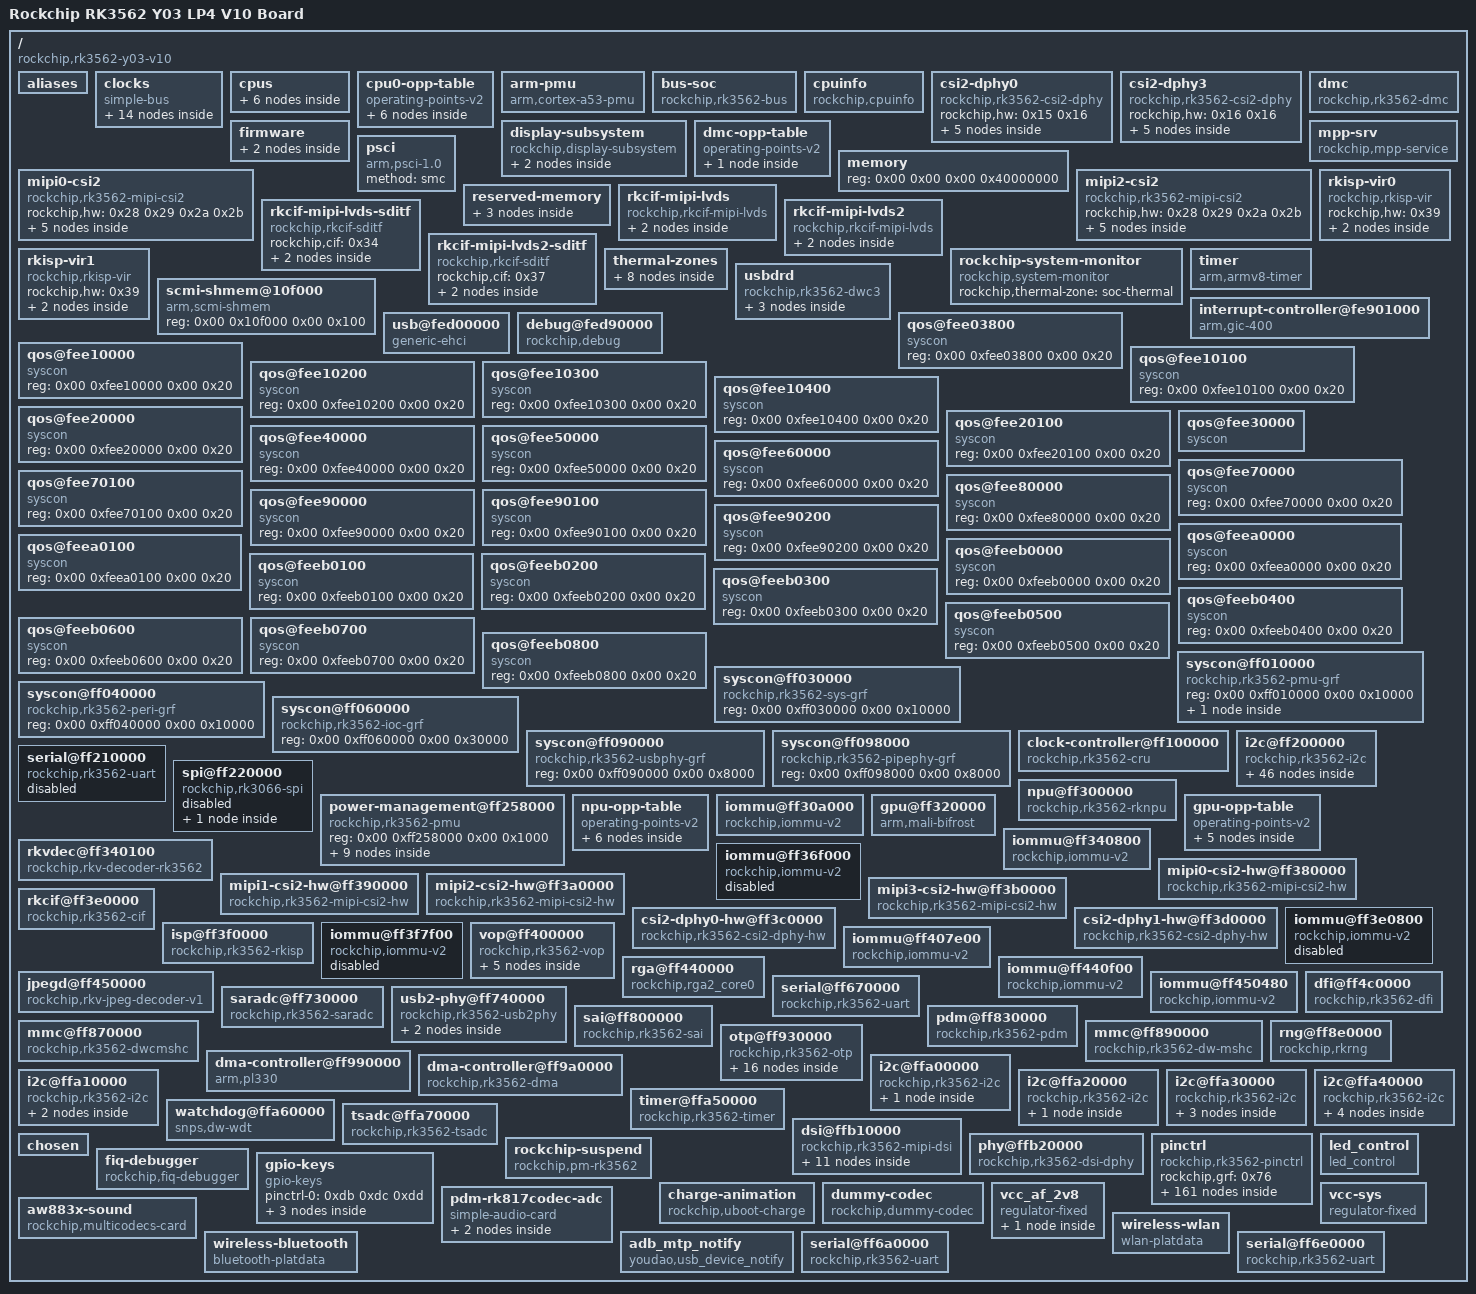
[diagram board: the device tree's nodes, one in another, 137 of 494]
/dts-v1/;

/ {
	compatible = "rockchip,rk3562-y03-v10", "rockchip,rk3562";
	interrupt-parent = <0x01>;
	#address-cells = <0x02>;
	#size-cells = <0x02>;
	model = "Rockchip RK3562 Y03 LP4 V10 Board";

	aliases {
		csi2dphy0 = "/csi2-dphy0";
		csi2dphy3 = "/csi2-dphy3";
		gpio0 = "/pinctrl/gpio@ff260000";
		gpio1 = "/pinctrl/gpio@ff620000";
		gpio2 = "/pinctrl/gpio@ff630000";
		gpio3 = "/pinctrl/gpio@ffac0000";
		gpio4 = "/pinctrl/gpio@ffad0000";
		i2c0 = "/i2c@ff200000";
		i2c1 = "/i2c@ffa00000";
		i2c2 = "/i2c@ffa10000";
		i2c3 = "/i2c@ffa20000";
		i2c4 = "/i2c@ffa30000";
		i2c5 = "/i2c@ffa40000";
		rkcif_mipi_lvds0 = "/rkcif-mipi-lvds";
		rkcif_mipi_lvds2 = "/rkcif-mipi-lvds2";
		serial0 = "/serial@ff210000";
		serial1 = "/serial@ff670000";
		spi0 = "/spi@ff220000";
		mmc0 = "/mmc@ff870000";
		mmc1 = "/mmc@ff890000";
		serial4 = "/serial@ff6a0000";
		serial8 = "/serial@ff6e0000";
	};

	clocks {
		compatible = "simple-bus";
		#address-cells = <0x02>;
		#size-cells = <0x02>;
		ranges;

		xin32k {
			compatible = "fixed-clock";
			#clock-cells = <0x00>;
			clock-frequency = <0x8000>;
			clock-output-names = "xin32k";
		};

		xin24m {
			compatible = "fixed-clock";
			#clock-cells = <0x00>;
			clock-frequency = <0x16e3600>;
			clock-output-names = "xin24m";
		};

		hclk_vepu@ff100324 {
			compatible = "rockchip,rk3562-clock-gate-link";
			reg = <0x00 0xff100324 0x00 0x10>;
			clock-names = "link";
			clocks = <0x02 0x152>;
			#power-domain-cells = <0x01>;
			#clock-cells = <0x00>;
		};

		aclk_vdpu@ff100328 {
			compatible = "rockchip,rk3562-clock-gate-link";
			reg = <0x00 0xff100328 0x00 0x10>;
			clock-names = "link";
			clocks = <0x02 0x12>;
			#power-domain-cells = <0x01>;
			#clock-cells = <0x00>;
		};

		aclk_vi_isp@ff10032c {
			compatible = "rockchip,rk3562-clock-gate-link";
			reg = <0x00 0xff10032c 0x00 0x10>;
			clock-names = "link";
			clocks = <0x02 0x12>;
			#power-domain-cells = <0x01>;
			#clock-cells = <0x00>;
			phandle = <0x03>;
		};

		aclk_vo@ff100334 {
			compatible = "rockchip,rk3562-clock-gate-link";
			reg = <0x00 0xff100334 0x00 0x10>;
			clock-names = "link";
			clocks = <0x02 0x12>;
			#power-domain-cells = <0x01>;
			#clock-cells = <0x00>;
			phandle = <0x04>;
		};

		aclk_vepu@ff100324 {
			compatible = "rockchip,rk3562-clock-gate-link";
			reg = <0x00 0xff100324 0x00 0x10>;
			clock-names = "link";
			clocks = <0x03>;
			#power-domain-cells = <0x01>;
			#clock-cells = <0x00>;
		};

		aclk_rga_jdec@ff100338 {
			compatible = "rockchip,rk3562-clock-gate-link";
			reg = <0x00 0xff100338 0x00 0x10>;
			clock-names = "link";
			clocks = <0x04>;
			#power-domain-cells = <0x01>;
			#clock-cells = <0x00>;
		};

		mclkin-sai0 {
			compatible = "fixed-clock";
			#clock-cells = <0x00>;
			clock-frequency = <0x00>;
			clock-output-names = "mclk_sai0_from_io";
		};

		mclkin-sai1 {
			compatible = "fixed-clock";
			#clock-cells = <0x00>;
			clock-frequency = <0x00>;
			clock-output-names = "mclk_sai1_from_io";
		};

		mclkin-sai2 {
			compatible = "fixed-clock";
			#clock-cells = <0x00>;
			clock-frequency = <0x00>;
			clock-output-names = "mclk_sai2_from_io";
		};

		mclkout-sai0@ff040070 {
			compatible = "rockchip,clk-out";
			reg = <0x00 0xff040070 0x00 0x04>;
			clocks = <0x02 0x79>;
			#clock-cells = <0x00>;
			clock-output-names = "mclk_sai0_to_io";
			rockchip,bit-shift = <0x04>;
			phandle = <0x51>;
		};

		mclkout-sai1@ff040070 {
			compatible = "rockchip,clk-out";
			reg = <0x00 0xff040070 0x00 0x04>;
			clocks = <0x02 0x7f>;
			#clock-cells = <0x00>;
			clock-output-names = "mclk_sai1_to_io";
			rockchip,bit-shift = <0x09>;
		};

		mclkout-sai2@ff040070 {
			compatible = "rockchip,clk-out";
			reg = <0x00 0xff040070 0x00 0x04>;
			clocks = <0x02 0x85>;
			#clock-cells = <0x00>;
			clock-output-names = "mclk_sai2_to_io";
			rockchip,bit-shift = <0x0b>;
		};
	};

	cpus {
		#address-cells = <0x02>;
		#size-cells = <0x00>;

		cpu@0 {
			device_type = "cpu";
			compatible = "arm,cortex-a53";
			reg = <0x00 0x00>;
			enable-method = "psci";
			clocks = <0x05 0x08>;
			cpu-idle-states = <0x06>;
			operating-points-v2 = <0x07>;
			#cooling-cells = <0x02>;
			dynamic-power-coefficient = <0x8a>;
			cpu-supply = <0x08>;
			phandle = <0x0e>;
		};

		cpu@1 {
			device_type = "cpu";
			compatible = "arm,cortex-a53";
			reg = <0x00 0x01>;
			enable-method = "psci";
			clocks = <0x05 0x08>;
			cpu-idle-states = <0x06>;
			operating-points-v2 = <0x07>;
			#cooling-cells = <0x02>;
			dynamic-power-coefficient = <0x8a>;
			phandle = <0x0f>;
		};

		cpu@2 {
			device_type = "cpu";
			compatible = "arm,cortex-a53";
			reg = <0x00 0x02>;
			enable-method = "psci";
			clocks = <0x05 0x08>;
			cpu-idle-states = <0x06>;
			operating-points-v2 = <0x07>;
			#cooling-cells = <0x02>;
			dynamic-power-coefficient = <0x8a>;
			phandle = <0x10>;
		};

		cpu@3 {
			device_type = "cpu";
			compatible = "arm,cortex-a53";
			reg = <0x00 0x03>;
			enable-method = "psci";
			clocks = <0x05 0x08>;
			cpu-idle-states = <0x06>;
			operating-points-v2 = <0x07>;
			#cooling-cells = <0x02>;
			dynamic-power-coefficient = <0x8a>;
			phandle = <0x11>;
		};

		idle-states {
			entry-method = "psci";

			cpu-sleep {
				compatible = "arm,idle-state";
				local-timer-stop;
				arm,psci-suspend-param = <0x10000>;
				entry-latency-us = <0x78>;
				exit-latency-us = <0xfa>;
				min-residency-us = <0x384>;
				phandle = <0x06>;
			};
		};
	};

	cpu0-opp-table {
		compatible = "operating-points-v2";
		opp-shared;
		mbist-vmin = <0xc96a8 0xdbba0 0xee098>;
		nvmem-cells = <0x09 0x0a 0x0b 0x0c>;
		nvmem-cell-names = "leakage", "opp-info", "mbist-vmin", "pvtm";
		rockchip,pvtm-voltage-sel = <0x00 0x500 0x00 0x501 0x546 0x00 0x547 0x58c 0x00 0x58d 0x5d2 0x00 0x5d3 0x270f 0x00>;
		rockchip,pvtm-pvtpll;
		rockchip,pvtm-offset = <0x634>;
		rockchip,pvtm-sample-time = <0x44c>;
		rockchip,pvtm-freq = <0x188940>;
		rockchip,pvtm-volt = <0xdbba0>;
		rockchip,pvtm-ref-temp = <0x28>;
		rockchip,pvtm-temp-prop = <0x00 0x00>;
		rockchip,pvtm-thermal-zone = "soc-thermal";
		rockchip,grf = <0x0d>;
		rockchip,temp-hysteresis = <0x1388>;
		rockchip,low-temp = <0x2710>;
		rockchip,low-temp-min-volt = <0xe1d48>;
		phandle = <0x07>;

		opp-408000000 {
			opp-hz = <0x00 0x18519600>;
			opp-microvolt = <0xc96a8 0xc96a8 0x118c30>;
			clock-latency-ns = <0x9c40>;
		};

		opp-600000000 {
			opp-hz = <0x00 0x23c34600>;
			opp-microvolt = <0xc96a8 0xc96a8 0x118c30>;
			clock-latency-ns = <0x9c40>;
		};

		opp-816000000 {
			opp-hz = <0x00 0x30a32c00>;
			opp-microvolt = <0xc96a8 0xc96a8 0x118c30>;
			clock-latency-ns = <0x9c40>;
		};

		opp-1008000000 {
			opp-hz = <0x00 0x3c14dc00>;
			opp-microvolt = <0xcf850 0xcf850 0x118c30>;
			opp-microvolt-L0 = <0xcf850 0xcf850 0x118c30>;
			opp-microvolt-L1 = <0xc96a8 0xc96a8 0x118c30>;
			opp-microvolt-L2 = <0xc96a8 0xc96a8 0x118c30>;
			opp-microvolt-L3 = <0xc96a8 0xc96a8 0x118c30>;
			opp-microvolt-L4 = <0xc96a8 0xc96a8 0x118c30>;
			clock-latency-ns = <0x9c40>;
		};

		opp-1200000000 {
			opp-hz = <0x00 0x47868c00>;
			opp-microvolt = <0xe1d48 0xe1d48 0x118c30>;
			opp-microvolt-L0 = <0xe1d48 0xe1d48 0x118c30>;
			opp-microvolt-L1 = <0xdbba0 0xdbba0 0x118c30>;
			opp-microvolt-L2 = <0xd59f8 0xd59f8 0x118c30>;
			opp-microvolt-L3 = <0xcf850 0xcf850 0x118c30>;
			opp-microvolt-L4 = <0xc96a8 0xc96a8 0x118c30>;
			clock-latency-ns = <0x9c40>;
			opp-suspend;
		};

		opp-1416000000 {
			opp-hz = <0x00 0x54667200>;
			opp-microvolt = <0xf4240 0xf4240 0x118c30>;
			opp-microvolt-L0 = <0xf4240 0xf4240 0x118c30>;
			opp-microvolt-L1 = <0xee098 0xee098 0x118c30>;
			opp-microvolt-L2 = <0xe7ef0 0xe7ef0 0x118c30>;
			opp-microvolt-L3 = <0xe1d48 0xe1d48 0x118c30>;
			opp-microvolt-L4 = <0xdbba0 0xdbba0 0x118c30>;
			clock-latency-ns = <0x9c40>;
		};
	};

	arm-pmu {
		compatible = "arm,cortex-a53-pmu";
		interrupts = <0x00 0xe4 0x04 0x00 0xe5 0x04 0x00 0xe6 0x04 0x00 0xe7 0x04>;
		interrupt-affinity = <0x0e 0x0f 0x10 0x11>;
	};

	bus-soc {
		compatible = "rockchip,rk3562-bus";
		rockchip,busfreq-policy = "smc";
		rockchip,soc-bus-table = <0x00 0xa000a8 0x7001 0x01 0xa000a8 0x7c39 0x02 0xa000a8 0x7c39 0x03 0xa000a8 0x7c39 0x04 0xa000a5 0xb007 0x05 0xa000a8 0x7034 0x06 0xa000a8 0x7034 0x07 0xa000a8 0x7034 0x08 0xa000a8 0x7001>;
	};

	cpuinfo {
		compatible = "rockchip,cpuinfo";
		nvmem-cells = <0x12 0x13 0x14>;
		nvmem-cell-names = "id", "cpu-version", "cpu-code";
	};

	csi2-dphy0 {
		compatible = "rockchip,rk3562-csi2-dphy";
		rockchip,hw = <0x15 0x16>;
		status = "okay";

		ports {
			#address-cells = <0x01>;
			#size-cells = <0x00>;

			port@0 {
				reg = <0x00>;
				#address-cells = <0x01>;
				#size-cells = <0x00>;

				endpoint@1 {
					reg = <0x01>;
					remote-endpoint = <0x17>;
					data-lanes = <0x01>;
					phandle = <0xb8>;
				};
			};

			port@1 {
				reg = <0x01>;
				#address-cells = <0x01>;
				#size-cells = <0x00>;

				endpoint@0 {
					reg = <0x00>;
					remote-endpoint = <0x18>;
					phandle = <0x2c>;
				};
			};
		};
	};

	csi2-dphy3 {
		compatible = "rockchip,rk3562-csi2-dphy";
		rockchip,hw = <0x16 0x16>;
		status = "okay";

		ports {
			#address-cells = <0x01>;
			#size-cells = <0x00>;

			port@0 {
				reg = <0x00>;
				#address-cells = <0x01>;
				#size-cells = <0x00>;

				endpoint@1 {
					reg = <0x01>;
					remote-endpoint = <0x19>;
					data-lanes = <0x01 0x02 0x03 0x04>;
					phandle = <0xbe>;
				};
			};

			port@1 {
				reg = <0x01>;
				#address-cells = <0x01>;
				#size-cells = <0x00>;

				endpoint@0 {
					reg = <0x00>;
					remote-endpoint = <0x1a>;
					phandle = <0x2e>;
				};
			};
		};
	};

	display-subsystem {
		compatible = "rockchip,display-subsystem";
		ports = <0x1b>;
		status = "okay";
		memory-region = <0x1c 0x1d>;
		memory-region-names = "drm-logo", "drm-cubic-lut";

		route {

			route-dsi {
				status = "okay";
				logo,uboot = "logo_kernel.bmp";
				logo,kernel = "logo_kernel.bmp";
				logo,mode = "center";
				charge_logo,mode = "center";
				connect = <0x1e>;
			};
		};
	};

	dmc {
		compatible = "rockchip,rk3562-dmc";
		interrupts = <0x00 0x76 0x04>;
		interrupt-names = "complete";
		devfreq-events = <0x21>;
		clocks = <0x05 0x0b>;
		clock-names = "dmc_clk";
		operating-points-v2 = <0x22>;
		upthreshold = <0x28>;
		downdifferential = <0x14>;
		system-status-level = <0x01 0x04 0x08 0x08 0x02 0x01 0x10 0x04 0x10000 0x04 0x1000 0x08 0x4000 0x08 0x2000 0x08 0xc00 0x08>;
		auto-min-freq = <0x4f1a0>;
		auto-freq-en = <0x00>;
		#cooling-cells = <0x02>;
		status = "okay";
		center-supply = <0x23>;
	};

	dmc-opp-table {
		compatible = "operating-points-v2";
		mbist-vmin = <0xcf850 0xdbba0 0xe1d48>;
		nvmem-cells = <0x24 0x25 0x26>;
		nvmem-cell-names = "leakage", "opp-info", "mbist-vmin";
		rockchip,temp-hysteresis = <0x1388>;
		rockchip,low-temp = <0x2710>;
		rockchip,low-temp-min-volt = <0xdbba0>;
		rockchip,leakage-voltage-sel = <0x01 0x0f 0x00 0x10 0x14 0x01 0x15 0xfe 0x02>;
		phandle = <0x22>;

		opp-1560000000 {
			opp-hz = <0x00 0x5cfbb600>;
			opp-microvolt = <0xdbba0 0xdbba0 0xe7ef0>;
			opp-microvolt-L0 = <0xdbba0 0xdbba0 0xe7ef0>;
			opp-microvolt-L1 = <0xd59f8 0xd59f8 0xe7ef0>;
			opp-microvolt-L2 = <0xcf850 0xcf850 0xe7ef0>;
		};
	};

	firmware {

		scmi {
			compatible = "arm,scmi-smc";
			shmem = <0x27>;
			arm,smc-id = <0x82000010>;
			#address-cells = <0x01>;
			#size-cells = <0x00>;

			protocol@14 {
				reg = <0x14>;
				#clock-cells = <0x01>;
				assigned-clocks = <0x05 0x08>;
				assigned-clock-rates = <0x3c14dc00>;
				phandle = <0x05>;
			};
		};
	};

	memory {
		device_type = "memory";
		reg = <0x00 0x00 0x00 0x40000000>;
	};

	mpp-srv {
		compatible = "rockchip,mpp-service";
		rockchip,taskqueue-count = <0x03>;
		rockchip,resetgroup-count = <0x03>;
		status = "okay";
		phandle = <0x72>;
	};

	mipi0-csi2 {
		compatible = "rockchip,rk3562-mipi-csi2";
		rockchip,hw = <0x28 0x29 0x2a 0x2b>;
		status = "okay";

		ports {
			#address-cells = <0x01>;
			#size-cells = <0x00>;

			port@0 {
				reg = <0x00>;
				#address-cells = <0x01>;
				#size-cells = <0x00>;

				endpoint@1 {
					reg = <0x01>;
					remote-endpoint = <0x2c>;
					phandle = <0x18>;
				};
			};

			port@1 {
				reg = <0x01>;
				#address-cells = <0x01>;
				#size-cells = <0x00>;

				endpoint@0 {
					reg = <0x00>;
					remote-endpoint = <0x2d>;
					phandle = <0x33>;
				};
			};
		};
	};

	mipi2-csi2 {
		compatible = "rockchip,rk3562-mipi-csi2";
		rockchip,hw = <0x28 0x29 0x2a 0x2b>;
		status = "okay";

		ports {
			#address-cells = <0x01>;
			#size-cells = <0x00>;

			port@0 {
				reg = <0x00>;
				#address-cells = <0x01>;
				#size-cells = <0x00>;

				endpoint@1 {
					reg = <0x01>;
					remote-endpoint = <0x2e>;
					data-lanes = <0x01 0x02 0x03 0x04>;
					phandle = <0x1a>;
				};
			};

			port@1 {
				reg = <0x01>;
				#address-cells = <0x01>;
				#size-cells = <0x00>;

				endpoint@0 {
					reg = <0x00>;
					remote-endpoint = <0x2f>;
					data-lanes = <0x01 0x02 0x03 0x04>;
					phandle = <0x36>;
				};
			};
		};
	};

	psci {
		compatible = "arm,psci-1.0";
		method = "smc";
	};

	reserved-memory {
		#address-cells = <0x02>;
		#size-cells = <0x02>;
		ranges;

		ramoops@110000 {
			compatible = "ramoops";
			reg = <0x00 0x110000 0x00 0xe0000>;
			boot-log-size = <0x8000>;
			boot-log-count = <0x01>;
			console-size = <0x80000>;
			pmsg-size = <0x30000>;
			ftrace-size = <0x00>;
			record-size = <0x14000>;
		};

		drm-logo@00000000 {
			compatible = "rockchip,drm-logo";
			reg = <0x00 0x00 0x00 0x00>;
			phandle = <0x1c>;
		};

		drm-cubic-lut@00000000 {
			compatible = "rockchip,drm-cubic-lut";
			reg = <0x00 0x00 0x00 0x00>;
			phandle = <0x1d>;
		};
	};

	rkcif-mipi-lvds {
		compatible = "rockchip,rkcif-mipi-lvds";
		rockchip,hw = <0x30>;
		iommus = <0x31>;
		status = "okay";
		phandle = <0x34>;

		port {

			endpoint {
				remote-endpoint = <0x33>;
				phandle = <0x2d>;
			};
		};
	};

	rkcif-mipi-lvds-sditf {
		compatible = "rockchip,rkcif-sditf";
		rockchip,cif = <0x34>;
		status = "okay";

		port {

			endpoint {
				remote-endpoint = <0x35>;
				phandle = <0x3a>;
			};
		};
	};

	rkcif-mipi-lvds2 {
		compatible = "rockchip,rkcif-mipi-lvds";
		rockchip,hw = <0x30>;
		iommus = <0x31>;
		status = "okay";
		phandle = <0x37>;

		port {

			endpoint {
				remote-endpoint = <0x36>;
				phandle = <0x2f>;
			};
		};
	};

	rkcif-mipi-lvds2-sditf {
		compatible = "rockchip,rkcif-sditf";
		rockchip,cif = <0x37>;
		status = "okay";

		port {

			endpoint {
				remote-endpoint = <0x38>;
				phandle = <0x3b>;
			};
		};
	};

	rkisp-vir0 {
		compatible = "rockchip,rkisp-vir";
		rockchip,hw = <0x39>;
		status = "okay";

		port {
			#address-cells = <0x01>;
			#size-cells = <0x00>;

			endpoint@0 {
				reg = <0x00>;
				remote-endpoint = <0x3a>;
				phandle = <0x35>;
			};
		};
	};

	rkisp-vir1 {
		compatible = "rockchip,rkisp-vir";
		rockchip,hw = <0x39>;
		status = "okay";

		port {
			#address-cells = <0x01>;
			#size-cells = <0x00>;

			endpoint@1 {
				reg = <0x01>;
				remote-endpoint = <0x3b>;
				phandle = <0x38>;
			};
		};
	};

	rockchip-system-monitor {
		compatible = "rockchip,system-monitor";
		rockchip,thermal-zone = "soc-thermal";
	};

	thermal-zones {

		soc-thermal {
			polling-delay-passive = <0x14>;
			polling-delay = <0x3e8>;
			sustainable-power = <0x2ad>;
			thermal-sensors = <0x3c 0x00>;

			trips {

				trip-point-0 {
					temperature = <0x124f8>;
					hysteresis = <0x7d0>;
					type = "passive";
				};

				trip-point-1 {
					temperature = <0x14c08>;
					hysteresis = <0x7d0>;
					type = "passive";
					phandle = <0x3d>;
				};

				soc-crit {
					temperature = <0x1c138>;
					hysteresis = <0x7d0>;
					type = "critical";
				};
			};

			cooling-maps {

				map0 {
					trip = <0x3d>;
					cooling-device = <0x0e 0xffffffff 0xffffffff>;
					contribution = <0x400>;
				};

				map1 {
					trip = <0x3d>;
					cooling-device = <0x3e 0xffffffff 0xffffffff>;
					contribution = <0x400>;
				};
			};
		};
	};

	timer {
		compatible = "arm,armv8-timer";
		interrupts = <0x01 0x0d 0xf08 0x01 0x0e 0xf08 0x01 0x0b 0xf08 0x01 0x0a 0xf08>;
	};

	scmi-shmem@10f000 {
		compatible = "arm,scmi-shmem";
		reg = <0x00 0x10f000 0x00 0x100>;
		phandle = <0x27>;
	};

	usbdrd {
		compatible = "rockchip,rk3562-dwc3", "rockchip,rk3399-dwc3";
		clocks = <0x02 0x10e 0x02 0x10d 0x02 0x10c 0x02 0x106>;
		clock-names = "ref", "suspend", "bus", "pipe_clk";
		#address-cells = <0x02>;
		#size-cells = <0x02>;
		ranges;
		status = "okay";

		usb@fe500000 {
			compatible = "snps,dwc3";
			reg = <0x00 0xfe500000 0x00 0x400000>;
			interrupts = <0x00 0x95 0x04>;
			dr_mode = "otg";
			phys = <0x3f>;
			phy-names = "usb2-phy";
			phy_type = "utmi_wide";
			power-domains = <0x40 0x0f>;
			resets = <0x02 0x10a>;
			reset-names = "usb3-otg";
			snps,dis_enblslpm_quirk;
			snps,dis-u1-entry-quirk;
			snps,dis-u2-entry-quirk;
			snps,dis-u2-freeclk-exists-quirk;
			snps,dis-del-phy-power-chg-quirk;
			snps,dis-tx-ipgap-linecheck-quirk;
			snps,dis_rxdet_inp3_quirk;
			quirk-skip-phy-init;
			status = "okay";
			maximum-speed = "high-speed";
			snps,dis_u2_susphy_quirk;
			snps,usb2-lpm-disable;
			usb-role-switch;

			port {
				#address-cells = <0x01>;
				#size-cells = <0x00>;

				endpoint@0 {
					reg = <0x00>;
					remote-endpoint = <0x41>;
					phandle = <0x54>;
				};
			};
		};
	};

	interrupt-controller@fe901000 {
		compatible = "arm,gic-400";
		#interrupt-cells = <0x03>;
		#address-cells = <0x00>;
		interrupt-controller;
		reg = <0x00 0xfe901000 0x00 0x1000 0x00 0xfe902000 0x00 0x2000 0x00 0xfe904000 0x00 0x2000 0x00 0xfe906000 0x00 0x2000>;
		interrupts = <0x01 0x09 0xf08>;
		phandle = <0x01>;
	};

	usb@fed00000 {
		compatible = "generic-ehci";
		reg = <0x00 0xfed00000 0x00 0x40000>;
		interrupts = <0x00 0x96 0x04>;
		clocks = <0x02 0x9e 0x02 0x9f 0x42>;
		clock-names = "usbhost", "arbiter", "utmi";
		phys = <0x43>;
		phy-names = "usb2-phy";
		status = "okay";
		maximum-speed = "full-speed";
	};

	debug@fed90000 {
		compatible = "rockchip,debug";
		reg = <0x00 0xfed90000 0x00 0x2000 0x00 0xfed92000 0x00 0x2000 0x00 0xfed94000 0x00 0x2000 0x00 0xfed96000 0x00 0x2000>;
	};

	qos@fee03800 {
		compatible = "syscon";
		reg = <0x00 0xfee03800 0x00 0x20>;
	};

	qos@fee10000 {
		compatible = "syscon";
		reg = <0x00 0xfee10000 0x00 0x20>;
	};

	qos@fee10100 {
		compatible = "syscon";
		reg = <0x00 0xfee10100 0x00 0x20>;
	};

	qos@fee10200 {
		compatible = "syscon";
		reg = <0x00 0xfee10200 0x00 0x20>;
	};

	qos@fee10300 {
		compatible = "syscon";
		reg = <0x00 0xfee10300 0x00 0x20>;
	};

	qos@fee10400 {
		compatible = "syscon";
		reg = <0x00 0xfee10400 0x00 0x20>;
	};

	qos@fee20000 {
		compatible = "syscon";
		reg = <0x00 0xfee20000 0x00 0x20>;
	};

	qos@fee20100 {
		compatible = "syscon";
		reg = <0x00 0xfee20100 0x00 0x20>;
	};

	qos@fee30000 {
		compatible = "syscon";
		reg = <0x00 0xfee30000 0x00 0x20>;
		priority-init = <0x202>;
		phandle = <0x5c>;
	};

	qos@fee40000 {
		compatible = "syscon";
		reg = <0x00 0xfee40000 0x00 0x20>;
		phandle = <0x5d>;
	};

	qos@fee50000 {
		compatible = "syscon";
		reg = <0x00 0xfee50000 0x00 0x20>;
		phandle = <0x5e>;
	};

	qos@fee60000 {
		compatible = "syscon";
		reg = <0x00 0xfee60000 0x00 0x20>;
		phandle = <0x61>;
	};

	qos@fee70000 {
		compatible = "syscon";
		reg = <0x00 0xfee70000 0x00 0x20>;
		phandle = <0x5f>;
	};

	qos@fee70100 {
		compatible = "syscon";
		reg = <0x00 0xfee70100 0x00 0x20>;
		phandle = <0x60>;
	};

	qos@fee80000 {
		compatible = "syscon";
		reg = <0x00 0xfee80000 0x00 0x20>;
		phandle = <0x62>;
	};

	qos@fee90000 {
		compatible = "syscon";
		reg = <0x00 0xfee90000 0x00 0x20>;
		phandle = <0x65>;
	};

	qos@fee90100 {
		compatible = "syscon";
		reg = <0x00 0xfee90100 0x00 0x20>;
		phandle = <0x63>;
	};

	qos@fee90200 {
		compatible = "syscon";
		reg = <0x00 0xfee90200 0x00 0x20>;
		phandle = <0x64>;
	};

	qos@feea0000 {
		compatible = "syscon";
		reg = <0x00 0xfeea0000 0x00 0x20>;
		phandle = <0x66>;
	};

	qos@feea0100 {
		compatible = "syscon";
		reg = <0x00 0xfeea0100 0x00 0x20>;
		phandle = <0x67>;
	};

	qos@feeb0000 {
		compatible = "syscon";
		reg = <0x00 0xfeeb0000 0x00 0x20>;
	};

	qos@feeb0100 {
		compatible = "syscon";
		reg = <0x00 0xfeeb0100 0x00 0x20>;
	};

	qos@feeb0200 {
		compatible = "syscon";
		reg = <0x00 0xfeeb0200 0x00 0x20>;
	};

	qos@feeb0300 {
		compatible = "syscon";
		reg = <0x00 0xfeeb0300 0x00 0x20>;
	};

	qos@feeb0400 {
		compatible = "syscon";
		reg = <0x00 0xfeeb0400 0x00 0x20>;
	};

	qos@feeb0500 {
		compatible = "syscon";
		reg = <0x00 0xfeeb0500 0x00 0x20>;
	};

	qos@feeb0600 {
		compatible = "syscon";
		reg = <0x00 0xfeeb0600 0x00 0x20>;
	};

	qos@feeb0700 {
		compatible = "syscon";
		reg = <0x00 0xfeeb0700 0x00 0x20>;
	};

	qos@feeb0800 {
		compatible = "syscon";
		reg = <0x00 0xfeeb0800 0x00 0x20>;
	};

	syscon@ff010000 {
		compatible = "rockchip,rk3562-pmu-grf", "syscon", "simple-mfd";
		reg = <0x00 0xff010000 0x00 0x10000>;
		phandle = <0x7c>;

		reboot-mode {
			compatible = "syscon-reboot-mode";
			offset = <0x220>;
			mode-bootloader = <0x5242c301>;
			mode-charge = <0x5242c30b>;
			mode-fastboot = <0x5242c309>;
			mode-loader = <0x5242c301>;
			mode-normal = <0x5242c300>;
			mode-recovery = <0x5242c303>;
			mode-ums = <0x5242c30c>;
			mode-panic = <0x5242c307>;
			mode-watchdog = <0x5242c308>;
		};
	};

	syscon@ff030000 {
		compatible = "rockchip,rk3562-sys-grf", "syscon", "simple-mfd";
		reg = <0x00 0xff030000 0x00 0x10000>;
		phandle = <0x0d>;
	};

	syscon@ff040000 {
		compatible = "rockchip,rk3562-peri-grf", "syscon";
		reg = <0x00 0xff040000 0x00 0x10000>;
		phandle = <0x8e>;
	};

	syscon@ff060000 {
		compatible = "rockchip,rk3562-ioc-grf", "syscon", "simple-mfd";
		reg = <0x00 0xff060000 0x00 0x30000>;
		phandle = <0x76>;
	};

	syscon@ff090000 {
		compatible = "rockchip,rk3562-usbphy-grf", "syscon";
		reg = <0x00 0xff090000 0x00 0x8000>;
		phandle = <0x8c>;
	};

	syscon@ff098000 {
		compatible = "rockchip,rk3562-pipephy-grf", "syscon";
		reg = <0x00 0xff098000 0x00 0x8000>;
		phandle = <0x8f>;
	};

	clock-controller@ff100000 {
		compatible = "rockchip,rk3562-cru";
		reg = <0x00 0xff100000 0x00 0x40000>;
		rockchip,grf = <0x0d>;
		#clock-cells = <0x01>;
		#reset-cells = <0x01>;
		assigned-clocks = <0x02 0x02 0x02 0x05>;
		assigned-clock-rates = <0x46cf7100 0x3b9aca00>;
		phandle = <0x02>;
	};

	i2c@ff200000 {
		compatible = "rockchip,rk3562-i2c", "rockchip,rk3399-i2c";
		reg = <0x00 0xff200000 0x00 0x1000>;
		clocks = <0x02 0x126 0x02 0x125>;
		clock-names = "i2c", "pclk";
		interrupts = <0x00 0x0c 0x04>;
		pinctrl-names = "default";
		pinctrl-0 = <0x46>;
		#address-cells = <0x01>;
		#size-cells = <0x00>;
		status = "okay";
		clock-frequency = <0x61a80>;

		pmic@20 {
			compatible = "rockchip,rk817";
			reg = <0x20>;
			interrupt-parent = <0x47>;
			interrupts = <0x03 0x08>;
			pinctrl-names = "default", "pmic-sleep", "pmic-power-off", "pmic-reset";
			pinctrl-0 = <0x48>;
			pinctrl-1 = <0x49 0x4a>;
			pinctrl-2 = <0x4b 0x4c>;
			pinctrl-3 = <0x4b 0x4d>;
			rockchip,system-power-controller;
			wakeup-source;
			#clock-cells = <0x01>;
			clock-output-names = "rk808-clkout1", "rk808-clkout2";
			pmic-reset-func = <0x00>;
			not-save-power-en = <0x01>;
			vcc1-supply = <0x4e>;
			vcc2-supply = <0x4e>;
			vcc3-supply = <0x4e>;
			vcc4-supply = <0x4e>;
			vcc5-supply = <0x4e>;
			vcc6-supply = <0x4e>;
			vcc7-supply = <0x4e>;
			vcc8-supply = <0x4e>;
			vcc9-supply = <0x4f>;
			phandle = <0xe3>;

			pwrkey {
				status = "okay";
			};

			pinctrl_rk8xx {
				gpio-controller;
				#gpio-cells = <0x02>;

				rk817_slppin_null {
					pins = "gpio_slp";
					function = "pin_fun0";
				};

				rk817_slppin_slp {
					pins = "gpio_slp";
					function = "pin_fun1";
					phandle = <0x4a>;
				};

				rk817_slppin_pwrdn {
					pins = "gpio_slp";
					function = "pin_fun2";
					phandle = <0x4c>;
				};

				rk817_slppin_rst {
					pins = "gpio_slp";
					function = "pin_fun3";
					phandle = <0x4d>;
				};
			};

			regulators {

				DCDC_REG1 {
					regulator-always-on;
					regulator-boot-on;
					regulator-min-microvolt = "", "\f5";
					regulator-max-microvolt = <0x149970>;
					regulator-init-microvolt = <0xe7ef0>;
					regulator-ramp-delay = <0x1771>;
					regulator-initial-mode = <0x02>;
					regulator-name = "vdd_logic_0v9";
					phandle = <0x23>;

					regulator-state-mem {
						regulator-off-in-suspend;
						regulator-suspend-microvolt = <0xdbba0>;
					};
				};

				DCDC_REG2 {
					regulator-always-on;
					regulator-boot-on;
					regulator-min-microvolt = <0x7a120>;
					regulator-max-microvolt = <0x149970>;
					regulator-init-microvolt = <0x100590>;
					regulator-ramp-delay = <0x1771>;
					regulator-initial-mode = <0x02>;
					regulator-name = "vdd_cpu_npu_gpu";
					phandle = <0x08>;

					regulator-state-mem {
						regulator-off-in-suspend;
					};
				};

				DCDC_REG3 {
					regulator-always-on;
					regulator-boot-on;
					regulator-initial-mode = <0x02>;
					regulator-name = "vcc_1v8";
					regulator-min-microvolt = <0x1b7740>;
					regulator-max-microvolt = <0x1b7740>;
					phandle = <0x8b>;

					regulator-state-mem {
						regulator-on-in-suspend;
						regulator-suspend-microvolt = <0x1b7740>;
					};
				};

				DCDC_REG4 {
					regulator-always-on;
					regulator-boot-on;
					regulator-min-microvolt = <0x325aa0>;
					regulator-max-microvolt = <0x325aa0>;
					regulator-initial-mode = <0x02>;
					regulator-name = "vcc3v3";

					regulator-state-mem {
						regulator-on-in-suspend;
						regulator-suspend-microvolt = <0x325aa0>;
					};
				};

				LDO_REG1 {
					regulator-always-on;
					regulator-boot-on;
					regulator-min-microvolt = <0x1b7740>;
					regulator-max-microvolt = <0x1b7740>;
					regulator-name = "iovdd1v8_cam";
					phandle = <0xb6>;

					regulator-state-mem {
						regulator-off-in-suspend;
						regulator-suspend-microvolt = <0x1b7740>;
					};
				};

				LDO_REG2 {
					regulator-always-on;
					regulator-boot-on;
					regulator-min-microvolt = <0x124f80>;
					regulator-max-microvolt = <0x124f80>;
					regulator-name = "dvdd_1v2_cam";
					phandle = <0xbc>;

					regulator-state-mem {
						regulator-off-in-suspend;
					};
				};

				LDO_REG3 {
					regulator-always-on;
					regulator-boot-on;
					regulator-min-microvolt = <0xdbba0>;
					regulator-max-microvolt = <0xdbba0>;
					regulator-name = "vdda0v9_pmu";

					regulator-state-mem {
						regulator-on-in-suspend;
						regulator-suspend-microvolt = <0xdbba0>;
					};
				};

				LDO_REG4 {
					regulator-always-on;
					regulator-boot-on;
					regulator-min-microvolt = <0x1b7740>;
					regulator-max-microvolt = <0x1b7740>;
					regulator-name = "vccio1v8_acodec";

					regulator-state-mem {
						regulator-off-in-suspend;
					};
				};

				LDO_REG5 {
					regulator-always-on;
					regulator-boot-on;
					regulator-min-microvolt = <0x325aa0>;
					regulator-max-microvolt = <0x325aa0>;
					regulator-name = "vcc3v3_lcm";
					phandle = <0xc0>;

					regulator-state-mem {
						regulator-on-in-suspend;
					};
				};

				LDO_REG6 {
					regulator-always-on;
					regulator-boot-on;
					regulator-min-microvolt = <0x325aa0>;
					regulator-max-microvolt = <0x325aa0>;
					regulator-name = "vcc3v3_pmu";

					regulator-state-mem {
						regulator-on-in-suspend;
						regulator-suspend-microvolt = <0x325aa0>;
					};
				};

				LDO_REG7 {
					regulator-always-on;
					regulator-boot-on;
					regulator-min-microvolt = <0x1b7740>;
					regulator-max-microvolt = <0x1b7740>;
					regulator-name = "vcc1v8_lcm";
					phandle = <0xaa>;

					regulator-state-mem {
						regulator-on-in-suspend;
					};
				};

				LDO_REG8 {
					regulator-always-on;
					regulator-boot-on;
					regulator-min-microvolt = <0x16e360>;
					regulator-max-microvolt = <0x16e360>;
					regulator-name = "dvdd1v5_cam";
					phandle = <0xb7>;

					regulator-state-mem {
						regulator-off-in-suspend;
					};
				};

				LDO_REG9 {
					regulator-always-on;
					regulator-boot-on;
					regulator-min-microvolt = <0x2ab980>;
					regulator-max-microvolt = <0x2ab980>;
					regulator-name = "avdd2v8_cam";
					phandle = <0xb5>;

					regulator-state-mem {
						regulator-off-in-suspend;
					};
				};

				BOOST {
					regulator-always-on;
					regulator-boot-on;
					regulator-min-microvolt = <0x4c4b40>;
					regulator-max-microvolt = <0x4c4b40>;
					regulator-name = "boost";
					phandle = <0x4f>;

					regulator-state-mem {
						regulator-off-in-suspend;
					};
				};

				OTG_SWITCH {
					regulator-name = "otg_switch";
					phandle = <0x8d>;

					regulator-state-mem {
						regulator-off-in-suspend;
					};
				};
			};

			battery {
				compatible = "rk817,battery";
				ntc_table = <0x311b5 0x2e71a 0x2bf0f 0x29967 0x275fc 0x254a8 0x23549 0x217be 0x1fbea 0x1e1b1 0x1c8f9 0x1b1ab 0x19bae 0x186ef 0x1735a 0x160dd 0x14f66 0x13ee6 0x12f4d 0x1208f 0x1129d 0x1056b 0xf8ef 0xed1e 0xe1ed 0xd754 0xcd48 0xc3c4 0xbabd 0xb22e 0xaa10 0xa25c 0x9b0c 0x941b 0x8d83 0x8740 0x814d 0x7ba4 0x7644 0x7126 0x6c49 0x67a8 0x6340 0x5f0e 0x5b10 0x5742 0x53a2 0x502d 0x4ce2 0x49be 0x46c0 0x43e4 0x412b 0x3e91 0x3c15 0x39b6 0x3772 0x3548 0x3336 0x313c 0x2f59 0x2d8a 0x2bd0 0x2a29 0x2894 0x2710 0x259d 0x243a 0x22e5 0x219f 0x2067 0x1f3c 0x1e1d 0x1d0a 0x1c02 0x1b05 0x1a12 0x1929 0x184a 0x1773 0x16a5 0x15df 0x1521 0x146b 0x13bb 0x1313 0x1271 0x11d5 0x113f 0x10af 0x1024 0xf9f 0xf1e 0xea3 0xe2c 0xdb9 0xd4b 0xce0 0xc7a 0xc17 0xbb8 0xb5c 0xb04 0xaaf 0xa5d 0xa0d 0x9c1 0x977 0x930 0x8eb 0x8a9 0x869 0x82b 0x7ef 0x7b5 0x77d 0x747 0x713 0x6e1 0x6b0 0x681 0x653 0x627 0x5fd 0x5d3 0x5ac 0x585 0x560 0x53b 0x518 0x4f6 0x4d5 0x4b6 0x497 0x479 0x45c 0x440 0x424 0x40a 0x3f0 0x3d8 0x3bf 0x3a8 0x391 0x37b 0x366 0x351 0x33d 0x32a 0x317 0x304 0x2f2 0x2e1 0x2d0 0x2c0 0x2b0 0x2a0 0x291 0x283 0x274 0x267 0x259 0x24c 0x23f 0x233 0x227>;
				ntc_degree_from = <0x01 0x28>;
				ocv_table = <0xd48 0xe47 0xe61 0xe7b 0xe96 0xeab 0xec1 0xed4 0xee9 0xf02 0xf20 0xf4a 0xf83 0xfbc 0xff1 0x1029 0x1065 0x10a1 0x10dc 0x1110 0x1146>;
				design_capacity = <0x6a4>;
				design_qmax = <0x74e>;
				bat_res = <0xb1>;
				sleep_enter_current = <0x1e>;
				sleep_exit_current = <0x1e>;
				sleep_filter_current = <0x14>;
				power_off_thresd = <0xd48>;
				zero_algorithm_vol = <0xbb8>;
				max_soc_offset = <0x3c>;
				monitor_sec = <0x05>;
				sample_res = <0x19>;
				virtual_power = <0x00>;
				chrg_finish_cur = <0x32>;
			};

			charger {
				compatible = "rk817,charger";
				min_input_voltage = <0x1194>;
				max_input_current = <0x5dc>;
				max_chrg_current = <0x5dc>;
				max_chrg_voltage = <0x1162>;
				chrg_term_mode = <0x00>;
				chrg_finish_cur = <0x32>;
				virtual_power = <0x00>;
				dc_det_adc = <0x00>;
				sample_res = <0x19>;
				extcon = <0x42>;
				vsys_can_sd = <0x01>;
				otg5v_suspend_enable = <0x00>;
				status = "okay";
			};

			codec {
				#sound-dai-cells = <0x00>;
				compatible = "rockchip,rk817-codec";
				clocks = <0x51>;
				clock-names = "mclk";
				assigned-clocks = <0x51>;
				assigned-clock-rates = <0xbb8000>;
				pinctrl-names = "default";
				pinctrl-0 = <0x52>;
				i2s-module-disable;
				mic-in-differential;
				pdmdata-out-enable;
				status = "okay";
				phandle = <0xdf>;
			};
		};

		usb_type_c_aw35616@60 {
			compatible = "awinic,usb_type_c_aw35616";
			reg = <0x60>;
			interrupt-parent = <0x47>;
			interrupts = <0x15 0x08>;
			pinctrl-0 = <0x53>;
			pinctrl-names = "default";
			aw35616-tcpc,role_def = <0x05>;
			aw35616,rp_level = <0x00>;
			aw35616_acc_support = <0x00>;
			aw35616_toggle_cycle = <0x00>;
			status = "okay";
			phandle = <0xec>;

			connector {
				compatible = "usb-c-connector";
				label = "USB-C";
				data-role = "dual";

				ports {
					#address-cells = <0x01>;
					#size-cells = <0x00>;

					port@0 {
						reg = <0x00>;

						endpoint@0 {
							remote-endpoint = <0x54>;
							phandle = <0x41>;
						};
					};
				};
			};
		};
	};

	serial@ff210000 {
		compatible = "rockchip,rk3562-uart", "snps,dw-apb-uart";
		reg = <0x00 0xff210000 0x00 0x100>;
		interrupts = <0x00 0x1e 0x04>;
		clocks = <0x02 0x12b 0x02 0x127>;
		clock-names = "baudclk", "apb_pclk";
		reg-shift = <0x02>;
		reg-io-width = <0x04>;
		dmas = <0x55 0x00>;
		status = "disabled";
	};

	spi@ff220000 {
		compatible = "rockchip,rk3066-spi";
		reg = <0x00 0xff220000 0x00 0x1000>;
		interrupts = <0x00 0x34 0x04>;
		#address-cells = <0x01>;
		#size-cells = <0x00>;
		clocks = <0x02 0x12d 0x02 0x12c 0x02 0x12e>;
		clock-names = "spiclk", "apb_pclk", "sclk_in";
		dmas = <0x55 0x0d 0x55 0x0c>;
		dma-names = "tx", "rx";
		pinctrl-names = "default";
		pinctrl-0 = <0x56 0x57>;
		num-cs = <0x02>;
		status = "disabled";
		max-freq = <0x2faf080>;

		sitronix_ts_spi@0 {
			compatible = "sitronix_ts";
			reg = <0x00>;
			spi-max-frequency = <0x2faf080>;
			irq-gpio = <0x47 0x0d 0x02>;
			rst-gpio = <0x47 0x0e 0x00>;
			spi-cpha;
			spi-cpol;
		};
	};

	power-management@ff258000 {
		compatible = "rockchip,rk3562-pmu", "syscon", "simple-mfd";
		reg = <0x00 0xff258000 0x00 0x1000>;

		power-controller {
			compatible = "rockchip,rk3562-power-controller";
			#power-domain-cells = <0x01>;
			#address-cells = <0x01>;
			#size-cells = <0x00>;
			status = "okay";
			phandle = <0x40>;

			pd_gpu@8 {
				reg = <0x08>;
				pm_qos = <0x5c>;
			};

			pd_npu@7 {
				reg = <0x07>;
				pm_qos = <0x5d>;
			};

			pd_vdpu@11 {
				reg = <0x0b>;
				pm_qos = <0x5e>;
			};

			pd_vi@12 {
				reg = <0x0c>;
				#address-cells = <0x01>;
				#size-cells = <0x00>;
				pm_qos = <0x5f 0x60>;

				pd_vepu@10 {
					reg = <0x0a>;
					pm_qos = <0x61>;
				};
			};

			pd_vo@13 {
				reg = <0x0d>;
				#address-cells = <0x01>;
				#size-cells = <0x00>;
				pm_qos = <0x62>;

				pd_rga@14 {
					reg = <0x0e>;
					pm_qos = <0x63 0x64 0x65>;
				};
			};

			pd_php@15 {
				reg = <0x0f>;
				pm_qos = <0x66 0x67>;
			};
		};
	};

	npu@ff300000 {
		compatible = "rockchip,rk3562-rknpu";
		reg = <0x00 0xff300000 0x00 0x10000>;
		interrupts = <0x00 0x77 0x04>;
		clocks = <0x05 0x0a 0x02 0x0a 0x02 0x6f>;
		clock-names = "scmi_clk", "aclk", "hclk";
		assigned-clocks = <0x02 0x0a>;
		assigned-clock-rates = <0x23c34600>;
		resets = <0x02 0x64 0x02 0x65>;
		reset-names = "srst_a", "srst_h";
		power-domains = <0x40 0x07>;
		operating-points-v2 = <0x68>;
		iommus = <0x69>;
		status = "okay";
		rknpu-supply = <0x08>;
	};

	npu-opp-table {
		compatible = "operating-points-v2";
		mbist-vmin = <0xc96a8 0xdbba0 0xee098>;
		nvmem-cells = <0x6a 0x6b 0x0b 0x6c>;
		nvmem-cell-names = "leakage", "opp-info", "mbist-vmin", "pvtm";
		rockchip,pvtm-voltage-sel = <0x00 0x2f8 0x00 0x2f9 0x320 0x01 0x321 0x348 0x02 0x349 0x370 0x03 0x371 0x270f 0x04>;
		rockchip,pvtm-pvtpll;
		rockchip,pvtm-offset = <0x674>;
		rockchip,pvtm-sample-time = <0x44c>;
		rockchip,pvtm-freq = <0xdbba0>;
		rockchip,pvtm-volt = <0xdbba0>;
		rockchip,pvtm-ref-temp = <0x28>;
		rockchip,pvtm-temp-prop = <0x00 0x00>;
		rockchip,pvtm-thermal-zone = "soc-thermal";
		rockchip,grf = <0x0d>;
		rockchip,temp-hysteresis = <0x1388>;
		rockchip,low-temp = <0x2710>;
		rockchip,low-temp-min-volt = <0xe1d48>;
		phandle = <0x68>;

		opp-300000000 {
			opp-hz = <0x00 0x11e1a300>;
			opp-microvolt = <0xc96a8 0xc96a8 0xf4240>;
		};

		opp-400000000 {
			opp-hz = <0x00 0x17d78400>;
			opp-microvolt = <0xc96a8 0xc96a8 0xf4240>;
		};

		opp-500000000 {
			opp-hz = <0x00 0x1dcd6500>;
			opp-microvolt = <0xc96a8 0xc96a8 0xf4240>;
		};

		opp-600000000 {
			opp-hz = <0x00 0x23c34600>;
			opp-microvolt = <0xd59f8 0xd59f8 0xf4240>;
			opp-microvolt-L0 = <0xd59f8 0xd59f8 0xf4240>;
			opp-microvolt-L1 = <0xcf850 0xcf850 0xf4240>;
			opp-microvolt-L2 = <0xc96a8 0xc96a8 0xf4240>;
			opp-microvolt-L3 = <0xc96a8 0xc96a8 0xf4240>;
			opp-microvolt-L4 = <0xc96a8 0xc96a8 0xf4240>;
		};

		opp-700000000 {
			opp-hz = <0x00 0x29b92700>;
			opp-microvolt = <0xe1d48 0xe1d48 0xf4240>;
			opp-microvolt-L0 = <0xe1d48 0xe1d48 0xf4240>;
			opp-microvolt-L1 = <0xdbba0 0xdbba0 0xf4240>;
			opp-microvolt-L2 = <0xd59f8 0xd59f8 0xf4240>;
			opp-microvolt-L3 = <0xcf850 0xcf850 0xf4240>;
			opp-microvolt-L4 = <0xc96a8 0xc96a8 0xf4240>;
		};

		opp-800000000 {
			opp-hz = <0x00 0x2faf0800>;
			opp-microvolt = <0xee098 0xee098 0xf4240>;
			opp-microvolt-L0 = <0xee098 0xee098 0xf4240>;
			opp-microvolt-L1 = <0xe7ef0 0xe7ef0 0xf4240>;
			opp-microvolt-L2 = <0xe1d48 0xe1d48 0xf4240>;
			opp-microvolt-L3 = <0xdbba0 0xdbba0 0xf4240>;
			opp-microvolt-L4 = <0xd59f8 0xd59f8 0xf4240>;
		};
	};

	iommu@ff30a000 {
		compatible = "rockchip,iommu-v2";
		reg = <0x00 0xff30a000 0x00 0x40>;
		interrupts = <0x00 0x77 0x04>;
		interrupt-names = "rknpu_mmu";
		clocks = <0x02 0x0a 0x02 0x6f>;
		clock-names = "aclk", "iface";
		power-domains = <0x40 0x07>;
		#iommu-cells = <0x00>;
		status = "okay";
		phandle = <0x69>;
	};

	gpu@ff320000 {
		compatible = "arm,mali-bifrost";
		reg = <0x00 0xff320000 0x00 0x4000>;
		interrupts = <0x00 0x4b 0x04 0x00 0x4d 0x04 0x00 0x4c 0x04>;
		interrupt-names = "GPU", "MMU", "JOB";
		upthreshold = <0x28>;
		downdifferential = <0x0a>;
		clocks = <0x05 0x09 0x02 0x09 0x02 0x6b 0x02 0x69>;
		clock-names = "clk_mali", "clk_gpu", "clk_gpu_brg", "aclk_gpu";
		power-domains = <0x40 0x08>;
		operating-points-v2 = <0x6d>;
		#cooling-cells = <0x02>;
		dynamic-power-coefficient = <0x334>;
		status = "okay";
		mali-supply = <0x08>;
		phandle = <0x3e>;
	};

	gpu-opp-table {
		compatible = "operating-points-v2";
		mbist-vmin = <0xc96a8 0xdbba0 0xee098>;
		nvmem-cells = <0x6e 0x6f 0x0b 0x70>;
		nvmem-cell-names = "leakage", "opp-info", "mbist-vmin", "pvtm";
		rockchip,pvtm-voltage-sel = <0x00 0x30c 0x00 0x30d 0x334 0x01 0x335 0x35c 0x02 0x35d 0x384 0x03 0x385 0x270f 0x04>;
		rockchip,pvtm-pvtpll;
		rockchip,pvtm-offset = <0x654>;
		rockchip,pvtm-sample-time = <0x44c>;
		rockchip,pvtm-freq = <0xdbba0>;
		rockchip,pvtm-volt = <0xdbba0>;
		rockchip,pvtm-ref-temp = <0x28>;
		rockchip,pvtm-temp-prop = <0x00 0x00>;
		rockchip,pvtm-thermal-zone = "soc-thermal";
		rockchip,grf = <0x0d>;
		rockchip,temp-hysteresis = <0x1388>;
		rockchip,low-temp = <0x2710>;
		rockchip,low-temp-min-volt = <0xe1d48>;
		phandle = <0x6d>;

		opp-300000000 {
			opp-hz = <0x00 0x11e1a300>;
			opp-microvolt = <0xc96a8 0xc96a8 0xf4240>;
		};

		opp-400000000 {
			opp-hz = <0x00 0x17d78400>;
			opp-microvolt = <0xc96a8 0xc96a8 0xf4240>;
		};

		opp-500000000 {
			opp-hz = <0x00 0x1dcd6500>;
			opp-microvolt = <0xc96a8 0xc96a8 0xf4240>;
		};

		opp-600000000 {
			opp-hz = <0x00 0x23c34600>;
			opp-microvolt = <0xc96a8 0xc96a8 0xf4240>;
		};

		opp-700000000 {
			opp-hz = <0x00 0x29b92700>;
			opp-microvolt = <0xdbba0 0xdbba0 0xf4240>;
			opp-microvolt-L0 = <0xdbba0 0xdbba0 0xf4240>;
			opp-microvolt-L1 = <0xd59f8 0xd59f8 0xf4240>;
			opp-microvolt-L2 = <0xcf850 0xcf850 0xf4240>;
			opp-microvolt-L3 = <0xc96a8 0xc96a8 0xf4240>;
			opp-microvolt-L4 = <0xc96a8 0xc96a8 0xf4240>;
		};
	};

	rkvdec@ff340100 {
		compatible = "rockchip,rkv-decoder-rk3562", "rockchip,rkv-decoder-v2";
		reg = <0x00 0xff340100 0x00 0x400 0x00 0xff340000 0x00 0x100>;
		reg-names = "regs", "link";
		interrupts = <0x00 0x7a 0x04>;
		interrupt-names = "irq_dec";
		clocks = <0x02 0x14a 0x02 0x14b 0x02 0x148>;
		clock-names = "aclk_vcodec", "hclk_vcodec", "clk_hevc_cabac";
		rockchip,normal-rates = <0xbcd3d80 0x00 0x179a7b00>;
		assigned-clocks = <0x02 0x14a 0x02 0x148>;
		assigned-clock-rates = <0xbcd3d80 0x179a7b00>;
		resets = <0x02 0xa7 0x02 0xa8 0x02 0xa2>;
		reset-names = "video_a", "video_h", "video_hevc_cabac";
		power-domains = <0x40 0x0b>;
		iommus = <0x71>;
		rockchip,srv = <0x72>;
		rockchip,taskqueue-node = <0x00>;
		rockchip,resetgroup-node = <0x00>;
		rockchip,task-capacity = <0x10>;
		status = "okay";
	};

	iommu@ff340800 {
		compatible = "rockchip,iommu-v2";
		reg = <0x00 0xff340800 0x00 0x40 0x00 0xff340900 0x00 0x40>;
		interrupts = <0x00 0x7b 0x04>;
		interrupt-names = "rkvdec_mmu";
		clocks = <0x02 0x14a 0x02 0x14b 0x02 0x148>;
		clock-names = "aclk", "iface", "clk_hevc_cabac";
		power-domains = <0x40 0x0b>;
		rockchip,shootdown-entire;
		#iommu-cells = <0x00>;
		status = "okay";
		phandle = <0x71>;
	};

	iommu@ff36f000 {
		compatible = "rockchip,iommu-v2";
		reg = <0x00 0xff36f000 0x00 0x40>;
		interrupts = <0x00 0x89 0x04>;
		interrupt-names = "rkvenc_mmu";
		clocks = <0x02 0x14f 0x02 0x150>;
		clock-names = "aclk", "iface";
		power-domains = <0x40 0x0a>;
		rockchip,shootdown-entire;
		#iommu-cells = <0x00>;
		status = "disabled";
		phandle = <0x73>;
	};

	mipi0-csi2-hw@ff380000 {
		compatible = "rockchip,rk3562-mipi-csi2-hw";
		reg = <0x00 0xff380000 0x00 0x10000>;
		reg-names = "csihost_regs";
		interrupts = <0x00 0x52 0x04 0x00 0x53 0x04>;
		interrupt-names = "csi-intr1", "csi-intr2";
		clocks = <0x02 0x15e>;
		clock-names = "pclk_csi2host";
		resets = <0x02 0xc0>;
		reset-names = "srst_csihost_p";
		status = "okay";
		phandle = <0x28>;
	};

	mipi1-csi2-hw@ff390000 {
		compatible = "rockchip,rk3562-mipi-csi2-hw";
		reg = <0x00 0xff390000 0x00 0x10000>;
		reg-names = "csihost_regs";
		interrupts = <0x00 0x54 0x04 0x00 0x55 0x04>;
		interrupt-names = "csi-intr1", "csi-intr2";
		clocks = <0x02 0x15f>;
		clock-names = "pclk_csi2host";
		resets = <0x02 0xc1>;
		reset-names = "srst_csihost_p";
		status = "okay";
		phandle = <0x29>;
	};

	mipi2-csi2-hw@ff3a0000 {
		compatible = "rockchip,rk3562-mipi-csi2-hw";
		reg = <0x00 0xff3a0000 0x00 0x10000>;
		reg-names = "csihost_regs";
		interrupts = <0x00 0x56 0x04 0x00 0x57 0x04>;
		interrupt-names = "csi-intr1", "csi-intr2";
		clocks = <0x02 0x160>;
		clock-names = "pclk_csi2host";
		resets = <0x02 0xc2>;
		reset-names = "srst_csihost_p";
		status = "okay";
		phandle = <0x2a>;
	};

	mipi3-csi2-hw@ff3b0000 {
		compatible = "rockchip,rk3562-mipi-csi2-hw";
		reg = <0x00 0xff3b0000 0x00 0x10000>;
		reg-names = "csihost_regs";
		interrupts = <0x00 0x1c 0x04 0x00 0x1d 0x04>;
		interrupt-names = "csi-intr1", "csi-intr2";
		clocks = <0x02 0x161>;
		clock-names = "pclk_csi2host";
		resets = <0x02 0xc3>;
		reset-names = "srst_csihost_p";
		status = "okay";
		phandle = <0x2b>;
	};

	csi2-dphy0-hw@ff3c0000 {
		compatible = "rockchip,rk3562-csi2-dphy-hw";
		reg = <0x00 0xff3c0000 0x00 0x10000>;
		clocks = <0x02 0x162>;
		clock-names = "pclk";
		resets = <0x02 0xc4>;
		reset-names = "srst_p_csiphy0";
		rockchip,grf = <0x0d>;
		status = "okay";
		phandle = <0x15>;
	};

	csi2-dphy1-hw@ff3d0000 {
		compatible = "rockchip,rk3562-csi2-dphy-hw";
		reg = <0x00 0xff3d0000 0x00 0x10000>;
		clocks = <0x02 0x163>;
		clock-names = "pclk";
		resets = <0x02 0xc5>;
		reset-names = "srst_p_csiphy1";
		rockchip,grf = <0x0d>;
		status = "okay";
		phandle = <0x16>;
	};

	rkcif@ff3e0000 {
		compatible = "rockchip,rk3562-cif";
		reg = <0x00 0xff3e0000 0x00 0x800>;
		reg-names = "cif_regs";
		interrupts = <0x00 0x63 0x04>;
		interrupt-names = "cif-intr";
		clocks = <0x02 0x157 0x02 0x158 0x02 0x159 0x02 0x15a 0x02 0x15b 0x02 0x15c 0x02 0x15d>;
		clock-names = "aclk_cif", "hclk_cif", "dclk_cif", "csirx0_data", "csirx1_data", "csirx2_data", "csirx3_data";
		resets = <0x02 0xb9 0x02 0xba 0x02 0xbb 0x02 0xbc 0x02 0xbd 0x02 0xbe 0x02 0xbf>;
		reset-names = "rst_cif_a", "rst_cif_h", "rst_cif_d", "rst_cif_i0", "rst_cif_i1", "rst_cif_i2", "rst_cif_i3";
		power-domains = <0x40 0x0c>;
		rockchip,grf = <0x0d>;
		iommus = <0x31>;
		status = "okay";
		phandle = <0x30>;
	};

	iommu@ff3e0800 {
		compatible = "rockchip,iommu-v2";
		reg = <0x00 0xff3e0800 0x00 0x100>;
		interrupts = <0x00 0x64 0x04>;
		interrupt-names = "cif_mmu";
		clocks = <0x02 0x157 0x02 0x158>;
		clock-names = "aclk", "iface";
		power-domains = <0x40 0x0c>;
		rockchip,disable-mmu-reset;
		#iommu-cells = <0x00>;
		status = "disabled";
		phandle = <0x31>;
	};

	isp@ff3f0000 {
		compatible = "rockchip,rk3562-rkisp";
		reg = <0x00 0xff3f0000 0x00 0x7f00>;
		interrupts = <0x00 0x58 0x04 0x00 0x59 0x04 0x00 0x5a 0x04>;
		interrupt-names = "mipi_irq", "mi_irq", "isp_irq";
		clocks = <0x02 0x154 0x02 0x155 0x02 0x156>;
		clock-names = "aclk_isp", "hclk_isp", "clk_isp_core";
		power-domains = <0x40 0x0c>;
		iommus = <0x74>;
		status = "okay";
		phandle = <0x39>;
	};

	iommu@ff3f7f00 {
		compatible = "rockchip,iommu-v2";
		reg = <0x00 0xff3f7f00 0x00 0x100>;
		interrupts = <0x00 0x5b 0x04>;
		interrupt-names = "isp_mmu";
		clocks = <0x02 0x154 0x02 0x155>;
		clock-names = "aclk", "iface";
		rockchip,disable-mmu-reset;
		#iommu-cells = <0x00>;
		power-domains = <0x40 0x0c>;
		status = "disabled";
		phandle = <0x74>;
	};

	vop@ff400000 {
		compatible = "rockchip,rk3562-vop";
		reg = <0x00 0xff400000 0x00 0x2000 0x00 0xff405000 0x00 0x1000>;
		reg-names = "regs", "gamma_lut";
		interrupts = <0x00 0x87 0x04>;
		clocks = <0x02 0x166 0x02 0x167 0x02 0x168>;
		clock-names = "aclk_vop", "hclk_vop", "dclk_vp0";
		resets = <0x02 0xd6 0x02 0xd7 0x02 0xd8>;
		reset-names = "axi", "ahb", "dclk_vp0";
		iommus = <0x75>;
		power-domains = <0x40 0x0d>;
		rockchip,grf = <0x76>;
		assigned-clocks = <0x02 0x168>;
		assigned-clock-parents = <0x02 0x02>;
		status = "okay";

		ports {
			#address-cells = <0x01>;
			#size-cells = <0x00>;
			phandle = <0x1b>;

			port@0 {
				#address-cells = <0x01>;
				#size-cells = <0x00>;
				reg = <0x00>;

				endpoint@0 {
					reg = <0x00>;
					remote-endpoint = <0x77>;
					phandle = <0x20>;
				};

				endpoint@1 {
					reg = <0x01>;
					remote-endpoint = <0x78>;
					phandle = <0x1e>;
				};

				endpoint@2 {
					reg = <0x02>;
					remote-endpoint = <0x79>;
					phandle = <0x1f>;
				};
			};
		};
	};

	iommu@ff407e00 {
		compatible = "rockchip,iommu-v2";
		reg = <0x00 0xff407e00 0x00 0x100>;
		interrupts = <0x00 0x87 0x04>;
		interrupt-names = "vop_mmu";
		clocks = <0x02 0x166 0x02 0x167>;
		clock-names = "aclk", "iface";
		#iommu-cells = <0x00>;
		rockchip,disable-device-link-resume;
		rockchip,shootdown-entire;
		status = "okay";
		phandle = <0x75>;
	};

	rga@ff440000 {
		compatible = "rockchip,rga2_core0";
		reg = <0x00 0xff440000 0x00 0x1000>;
		interrupts = <0x00 0x7e 0x04>;
		interrupt-names = "rga2_irq";
		clocks = <0x02 0x142 0x02 0x143 0x02 0x144>;
		clock-names = "aclk_rga2", "hclk_rga2", "clk_rga2";
		iommus = <0x7a>;
		power-domains = <0x40 0x0e>;
		status = "okay";
	};

	iommu@ff440f00 {
		compatible = "rockchip,iommu-v2";
		reg = <0x00 0xff440f00 0x00 0x100>;
		interrupts = <0x00 0x7e 0x04>;
		interrupt-names = "rga2_mmu";
		clocks = <0x02 0x142 0x02 0x143>;
		clock-names = "aclk", "iface";
		#iommu-cells = <0x00>;
		power-domains = <0x40 0x0e>;
		status = "okay";
		phandle = <0x7a>;
	};

	jpegd@ff450000 {
		compatible = "rockchip,rkv-jpeg-decoder-v1";
		reg = <0x00 0xff450000 0x00 0x400>;
		interrupts = <0x00 0x79 0x04>;
		clocks = <0x02 0x145 0x02 0x146>;
		clock-names = "aclk_vcodec", "hclk_vcodec";
		rockchip,disable-auto-freq;
		resets = <0x02 0xe9 0x02 0xea>;
		reset-names = "video_a", "video_h";
		power-domains = <0x40 0x0e>;
		iommus = <0x7b>;
		rockchip,srv = <0x72>;
		rockchip,taskqueue-node = <0x02>;
		rockchip,resetgroup-node = <0x02>;
		status = "okay";
	};

	iommu@ff450480 {
		compatible = "rockchip,iommu-v2";
		reg = <0x00 0xff450480 0x00 0x40>;
		interrupts = <0x00 0x78 0x04>;
		interrupt-names = "jpegd_mmu";
		clock-names = "aclk", "iface";
		clocks = <0x02 0x145 0x02 0x146>;
		power-domains = <0x40 0x0e>;
		rockchip,shootdown-entire;
		#iommu-cells = <0x00>;
		status = "okay";
		phandle = <0x7b>;
	};

	dfi@ff4c0000 {
		reg = <0x00 0xff4c0000 0x00 0x400>;
		compatible = "rockchip,rk3562-dfi";
		rockchip,pmugrf = <0x7c>;
		status = "okay";
		phandle = <0x21>;
	};

	serial@ff670000 {
		compatible = "rockchip,rk3562-uart", "snps,dw-apb-uart";
		reg = <0x00 0xff670000 0x00 0x100>;
		interrupts = <0x00 0x1f 0x04>;
		clocks = <0x02 0xb2 0x02 0xa6>;
		clock-names = "baudclk", "apb_pclk";
		reg-shift = <0x02>;
		reg-io-width = <0x04>;
		dmas = <0x55 0x0a 0x55 0x01>;
		status = "okay";
		pinctrl-names = "default";
		pinctrl-0 = <0x7d 0x7e>;
	};

	saradc@ff730000 {
		compatible = "rockchip,rk3562-saradc";
		reg = <0x00 0xff730000 0x00 0x100>;
		interrupts = <0x00 0x28 0x04>;
		#io-channel-cells = <0x01>;
		clocks = <0x02 0xfe 0x02 0xfd>;
		clock-names = "saradc", "apb_pclk";
		resets = <0x02 0xc0104>;
		reset-names = "saradc-apb";
		status = "okay";
		vref-supply = <0x8b>;
		phandle = <0x50>;
	};

	usb2-phy@ff740000 {
		compatible = "rockchip,rk3562-usb2phy";
		reg = <0x00 0xff740000 0x00 0x10000>;
		clocks = <0x02 0x13d 0x02 0xfb>;
		clock-names = "phyclk", "pclk";
		#clock-cells = <0x00>;
		clock-output-names = "usb480m_phy";
		rockchip,usbgrf = <0x8c>;
		status = "okay";
		phandle = <0x42>;

		otg-port {
			#phy-cells = <0x00>;
			interrupts = <0x00 0x99 0x04 0x00 0x9a 0x04 0x00 0x9b 0x04>;
			interrupt-names = "otg-bvalid", "otg-id", "linestate";
			status = "okay";
			vbus-supply = <0x8d>;
			phandle = <0x3f>;
		};

		host-port {
			#phy-cells = <0x00>;
			interrupts = <0x00 0x9c 0x04>;
			interrupt-names = "linestate";
			status = "okay";
			phandle = <0x43>;
		};
	};

	sai@ff800000 {
		compatible = "rockchip,rk3562-sai", "rockchip,sai-v1";
		reg = <0x00 0xff800000 0x00 0x1000>;
		interrupts = <0x00 0x4e 0x04>;
		clocks = <0x02 0x78 0x02 0x74>;
		clock-names = "mclk", "hclk";
		dmas = <0x55 0x13 0x55 0x12>;
		dma-names = "tx", "rx";
		resets = <0x02 0xc0023 0x02 0xc0020>;
		reset-names = "m", "h";
		pinctrl-names = "default";
		pinctrl-0 = <0x90 0x91 0x92 0x93>;
		#sound-dai-cells = <0x00>;
		status = "okay";
		phandle = <0xe0>;
	};

	pdm@ff830000 {
		compatible = "rockchip,rk3562-pdm", "rockchip,rv1126-pdm";
		reg = <0x00 0xff830000 0x00 0x1000>;
		clocks = <0x02 0x89 0x02 0x88>;
		clock-names = "pdm_clk", "pdm_hclk";
		dmas = <0x55 0x1f>;
		dma-names = "rx";
		pinctrl-names = "default";
		pinctrl-0 = <0xa2 0xa3>;
		#sound-dai-cells = <0x00>;
		status = "okay";
		rockchip,path-map = <0x01 0x00 0x02 0x03>;
		phandle = <0xde>;
	};

	mmc@ff870000 {
		compatible = "rockchip,rk3562-dwcmshc", "rockchip,rk3528-dwcmshc";
		reg = <0x00 0xff870000 0x00 0x10000>;
		interrupts = <0x00 0x3f 0x04>;
		assigned-clocks = <0x02 0x9a 0x02 0x99>;
		assigned-clock-rates = <0xbebc200 0xbebc200>;
		clocks = <0x02 0x99 0x02 0x97 0x02 0x98 0x02 0x9a 0x02 0x9b>;
		clock-names = "core", "bus", "axi", "block", "timer";
		resets = <0x02 0xc004a 0x02 0xc0048 0x02 0xc0049 0x02 0xc004b 0x02 0xc004c>;
		reset-names = "core", "bus", "axi", "block", "timer";
		max-frequency = <0xbebc200>;
		status = "okay";
		bus-width = <0x08>;
		no-sdio;
		no-sd;
		non-removable;
		mmc-hs400-1_8v;
		mmc-hs400-enhanced-strobe;
	};

	mmc@ff890000 {
		compatible = "rockchip,rk3562-dw-mshc", "rockchip,rk3288-dw-mshc";
		reg = <0x00 0xff890000 0x00 0x10000>;
		interrupts = <0x00 0x39 0x04>;
		max-frequency = <0x2faf080>;
		clocks = <0x02 0x91 0x02 0x92 0x02 0x95 0x02 0x96>;
		clock-names = "biu", "ciu", "ciu-drive", "ciu-sample";
		resets = <0x02 0xc0042>;
		reset-names = "reset";
		fifo-depth = <0x100>;
		status = "okay";
		no-sd;
		no-mmc;
		bus-width = <0x04>;
		disable-wp;
		cap-sd-highspeed;
		cap-sdio-irq;
		keep-power-in-suspend;
		pinctrl-names = "default";
		pinctrl-0 = <0xa6 0xa7 0xa8>;
		sd-uhs-sdr104;
	};

	rng@ff8e0000 {
		compatible = "rockchip,rkrng";
		reg = <0x00 0xff8e0000 0x00 0x200>;
		interrupts = <0x00 0x5d 0x04>;
		clocks = <0x05 0xe7>;
		clock-names = "hclk_trng";
		resets = <0x02 0xc00c7>;
		reset-names = "reset";
		status = "okay";
	};

	otp@ff930000 {
		compatible = "rockchip,rk3562-otp";
		reg = <0x00 0xff930000 0x00 0x4000>;
		#address-cells = <0x01>;
		#size-cells = <0x01>;
		clocks = <0x02 0xf5 0x02 0xf4 0x02 0xf3 0x02 0xf9 0x02 0xfa>;
		clock-names = "usr", "sbpi", "apb", "arb", "phy";
		resets = <0x02 0xc00e2 0x02 0xc00e1 0x02 0xc00e0 0x02 0xc00e6 0x02 0xc00e7>;
		reset-names = "usr", "sbpi", "apb", "arb", "phy";

		cpu-code@2 {
			reg = <0x02 0x02>;
			phandle = <0x14>;
		};

		cpu-version@8 {
			reg = <0x08 0x01>;
			bits = <0x03 0x03>;
			phandle = <0x13>;
		};

		mbist-vmin@9 {
			reg = <0x09 0x01>;
			bits = <0x00 0x02>;
			phandle = <0x0b>;
		};

		log-mbist-vmin@9 {
			reg = <0x09 0x01>;
			bits = <0x04 0x02>;
			phandle = <0x26>;
		};

		id@a {
			reg = <0x0a 0x10>;
			phandle = <0x12>;
		};

		cpu-leakage@1a {
			reg = <0x1a 0x01>;
			phandle = <0x09>;
		};

		log-leakage@1b {
			reg = <0x1b 0x01>;
			phandle = <0x24>;
		};

		npu-leakage@1c {
			reg = <0x1c 0x01>;
			phandle = <0x6a>;
		};

		gpu-leakage@1d {
			reg = <0x1d 0x01>;
			phandle = <0x6e>;
		};

		cpu-opp-info@2e {
			reg = <0x2e 0x06>;
			phandle = <0x0a>;
		};

		gpu-opp-info@34 {
			reg = <0x34 0x06>;
			phandle = <0x6f>;
		};

		npu-opp-info@3a {
			reg = <0x3a 0x06>;
			phandle = <0x6b>;
		};

		dmc-opp-info@40 {
			reg = <0x40 0x06>;
			phandle = <0x25>;
		};

		cpu-pvtpll@46 {
			reg = <0x46 0x02>;
			phandle = <0x0c>;
		};

		gpu-pvtpll@48 {
			reg = <0x48 0x02>;
			phandle = <0x70>;
		};

		npu-pvtpll@4a {
			reg = <0x4a 0x02>;
			phandle = <0x6c>;
		};
	};

	dma-controller@ff990000 {
		compatible = "arm,pl330", "arm,primecell";
		reg = <0x00 0xff990000 0x00 0x4000>;
		interrupts = <0x00 0x6f 0x04 0x00 0x6e 0x04>;
		clocks = <0x02 0xf1>;
		clock-names = "apb_pclk";
		#dma-cells = <0x01>;
		arm,pl330-periph-burst;
		phandle = <0x55>;
	};

	dma-controller@ff9a0000 {
		compatible = "rockchip,rk3562-dma", "rockchip,dma-v1";
		reg = <0x00 0xff9a0000 0x00 0x4000>;
		interrupts = <0x00 0x70 0x04>;
		clocks = <0x02 0xf2>;
		clock-names = "aclk";
		#dma-cells = <0x01>;
		dma-channels = <0x2a>;
		dma-requests = <0x2a>;
		rockchip,grf = <0x8e>;
	};

	i2c@ffa00000 {
		compatible = "rockchip,rk3562-i2c", "rockchip,rk3399-i2c";
		reg = <0x00 0xffa00000 0x00 0x1000>;
		clocks = <0x02 0x20 0x02 0x1a>;
		clock-names = "i2c", "pclk";
		interrupts = <0x00 0x0d 0x04>;
		pinctrl-names = "default";
		pinctrl-0 = <0xa9>;
		#address-cells = <0x01>;
		#size-cells = <0x00>;
		status = "okay";
		clock-frequency = <0x61a80>;

		hynitron@1a {
			compatible = "hyn,66xx";
			vcc_i2c-supply = <0xaa>;
			reg = <0x1a>;
			reset-gpio = <0x47 0x0f 0x00>;
			irq-gpio = <0x47 0x10 0x08>;
			max-touch-number = <0x05>;
			display-coords = <0x00 0x00 0x238 0x4ba>;
			pos-swap = <0x00>;
			posx-reverse = <0x00>;
			posy-reverse = <0x00>;
			status = "okay";
		};
	};

	i2c@ffa10000 {
		compatible = "rockchip,rk3562-i2c", "rockchip,rk3399-i2c";
		reg = <0x00 0xffa10000 0x00 0x1000>;
		clocks = <0x02 0x21 0x02 0x1b>;
		clock-names = "i2c", "pclk";
		interrupts = <0x00 0x0e 0x04>;
		pinctrl-names = "default";
		pinctrl-0 = <0xab>;
		#address-cells = <0x01>;
		#size-cells = <0x00>;
		status = "okay";
		clock-frequency = <0x61a80>;

		sensor@26 {
			status = "okay";
			compatible = "gs_mir3da";
			reg = <0x26>;
			type = <0x02>;
			irq-gpio = <0x47 0x05 0x02>;
			irq_enable = <0x01>;
			poll_delay_ms = <0x1e>;
			layout = <0x04>;
			pinctrl-0 = <0xac>;
			pinctrl-names = "default";
		};

		aw8680x@5c {
			compatible = "awinic,aw8680x";
			reg = <0x5c>;
			pinctrl-names = "default";
			pinctrl-0 = <0xad 0xae>;
			reset-gpio = <0x47 0x14 0x00>;
			wake-gpio = <0x47 0x13 0x00>;
			flash_boot_function_used;
			status = "okay";
		};
	};

	i2c@ffa20000 {
		compatible = "rockchip,rk3562-i2c", "rockchip,rk3399-i2c";
		reg = <0x00 0xffa20000 0x00 0x1000>;
		clocks = <0x02 0x22 0x02 0x1c>;
		clock-names = "i2c", "pclk";
		interrupts = <0x00 0x0f 0x04>;
		pinctrl-names = "default";
		pinctrl-0 = <0xaf>;
		#address-cells = <0x01>;
		#size-cells = <0x00>;
		status = "okay";
		clock-frequency = <0x61a80>;

		aw883xx@34 {
			compatible = "awinic,aw883xx_smartpa";
			reg = <0x34>;
			#sound-dai-cells = <0x00>;
			reset-gpio = <0xb0 0x0b 0x01>;
			irq-gpio = <0xb1 0x07 0x00>;
			pinctrl-0 = <0xb2>;
			pinctrl-names = "default";
			re-min = <0x3e8>;
			re-max = <0x9c40>;
			status = "okay";
			phandle = <0xe1>;
		};
	};

	i2c@ffa30000 {
		compatible = "rockchip,rk3562-i2c", "rockchip,rk3399-i2c";
		reg = <0x00 0xffa30000 0x00 0x1000>;
		clocks = <0x02 0x23 0x02 0x1d>;
		clock-names = "i2c", "pclk";
		interrupts = <0x00 0x10 0x04>;
		pinctrl-names = "default";
		pinctrl-0 = <0xb3>;
		#address-cells = <0x01>;
		#size-cells = <0x00>;
		status = "okay";
		clock-frequency = <0x61a80>;

		sc035gs@30 {
			compatible = "smartsens,sc035gs";
			status = "okay";
			reg = <0x30>;
			clocks = <0x02 0x13>;
			clock-names = "xvclk";
			pinctrl-names = "default";
			pinctrl-0 = <0xb4>;
			pwdn-gpios = <0xb1 0x10 0x00>;
			avdd-supply = <0xb5>;
			dovdd-supply = <0xb6>;
			dvdd-supply = <0xb7>;
			rockchip,camera-module-index = <0x00>;
			rockchip,camera-module-facing = "front";
			rockchip,camera-module-name = "default";
			rockchip,camera-module-lens-name = "default";

			port {

				endpoint {
					remote-endpoint = <0xb8>;
					data-lanes = <0x01>;
					phandle = <0x17>;
				};
			};
		};
	};

	i2c@ffa40000 {
		compatible = "rockchip,rk3562-i2c", "rockchip,rk3399-i2c";
		reg = <0x00 0xffa40000 0x00 0x1000>;
		clocks = <0x02 0x24 0x02 0x1e>;
		clock-names = "i2c", "pclk";
		interrupts = <0x00 0x11 0x04>;
		pinctrl-names = "default";
		pinctrl-0 = <0xb9>;
		#address-cells = <0x01>;
		#size-cells = <0x00>;
		status = "okay";

		dw9714@c {
			compatible = "dongwoon,dw9714";
			status = "okay";
			reg = <0x0c>;
			avdd-supply = <0xba>;
			rockchip,vcm-max-current = <0x3ff>;
			rockchip,vcm-start-current = <0x100>;
			rockchip,vcm-rated-current = <0x32a>;
			rockchip,vcm-step-mode = <0x06>;
			rockchip,camera-module-index = <0x01>;
			rockchip,camera-module-facing = "back";
			phandle = <0xbd>;
		};

		gc08a8@31 {
			status = "okay";
			compatible = "galaxycore,gc08a8";
			reg = <0x31>;
			clocks = <0x02 0x14>;
			clock-names = "xvclk";
			pinctrl-names = "default";
			pinctrl-0 = <0xbb>;
			pwdn-gpios = <0xb1 0x11 0x00>;
			avdd-supply = <0xb5>;
			dovdd-supply = <0xb6>;
			dvdd-supply = <0xbc>;
			rockchip,camera-module-index = <0x01>;
			rockchip,camera-module-facing = "back";
			rockchip,camera-module-name = "default";
			rockchip,camera-module-lens-name = "default_y03";
			lens-focus = <0xbd>;

			port {

				endpoint {
					remote-endpoint = <0xbe>;
					data-lanes = <0x01 0x02 0x03 0x04>;
					phandle = <0x19>;
				};
			};
		};
	};

	timer@ffa50000 {
		compatible = "rockchip,rk3562-timer", "rockchip,rk3288-timer";
		reg = <0x00 0xffa50000 0x00 0x20>;
		interrupts = <0x00 0x2d 0x04>;
		clocks = <0x02 0x28 0x02 0x29>;
		clock-names = "pclk", "timer";
	};

	watchdog@ffa60000 {
		compatible = "snps,dw-wdt";
		reg = <0x00 0xffa60000 0x00 0x100>;
		clocks = <0x02 0x33 0x02 0x32>;
		clock-names = "tclk", "pclk";
		interrupts = <0x00 0x66 0x04>;
		status = "okay";
	};

	tsadc@ffa70000 {
		compatible = "rockchip,rk3562-tsadc";
		reg = <0x00 0xffa70000 0x00 0x400>;
		rockchip,grf = <0x0d>;
		interrupts = <0x00 0x7d 0x04>;
		clocks = <0x02 0x41 0x02 0x42 0x02 0x40>;
		clock-names = "tsadc", "tsadc_tsen", "apb_pclk";
		assigned-clocks = <0x02 0x41 0x02 0x42>;
		assigned-clock-rates = <0x124f80 0xb71b00>;
		resets = <0x02 0x181 0x02 0x180 0x02 0x182>;
		reset-names = "tsadc", "tsadc-apb", "tsadc-phy";
		#thermal-sensor-cells = <0x01>;
		rockchip,hw-tshut-temp = <0x1d4c0>;
		rockchip,hw-tshut-mode = <0x00>;
		rockchip,hw-tshut-polarity = <0x00>;
		status = "okay";
		phandle = <0x3c>;
	};

	dsi@ffb10000 {
		compatible = "rockchip,rk3562-mipi-dsi";
		reg = <0x00 0xffb10000 0x00 0x10000>;
		interrupts = <0x00 0x84 0x04>;
		clocks = <0x02 0x4e>;
		clock-names = "pclk";
		resets = <0x02 0x199>;
		reset-names = "apb";
		phys = <0x44>;
		phy-names = "dphy";
		rockchip,grf = <0x0d>;
		#address-cells = <0x01>;
		#size-cells = <0x00>;
		status = "okay";

		ports {
			#address-cells = <0x01>;
			#size-cells = <0x00>;

			port@0 {
				reg = <0x00>;
				#address-cells = <0x01>;
				#size-cells = <0x00>;

				endpoint@0 {
					reg = <0x00>;
					remote-endpoint = <0x1e>;
					status = "okay";
					phandle = <0x78>;
				};
			};

			port@1 {
				reg = <0x01>;

				endpoint {
					remote-endpoint = <0xbf>;
					phandle = <0xc5>;
				};
			};
		};

		panel@0 {
			compatible = "simple-panel-dsi";
			reg = <0x00>;
			dsi,flags = <0xa03>;
			dsi,format = <0x00>;
			dsi,lanes = <0x02>;
			esd-type = <0x02>;
			power-supply = <0xaa>;
			vdd-supply = <0xc0>;
			enable-gpios = <0xb0 0x0f 0x00>;
			reset-gpios = <0xb0 0x0e 0x01>;
			pinctrl-names = "default";
			pinctrl-0 = <0xc1 0xc2 0xc3>;
			init-delay-ms = <0x0a>;
			enable-delay-ms = <0x0a>;
			prepare-delay-ms = <0x0a>;
			reset-delay-ms = <0x0a>;
			unprepare-delay-ms = <0x14>;
			disable-delay-ms = <0x32>;
			panel-init-sequence = <0x290004f0 0xa50ff029 0x26a11 0x290002fd 0x1a290002 0xea022900 0x2fd0029 0x2e000 0x29000bf8 0x00 0x00 0x2900 0x35103ff 0x5320111 0x50a0129>;
			panel-exit-sequence = <0x5280128 0x5320110>;

			display-timings {
				native-mode = <0xc4>;

				timing0 {
					clock-frequency = <0x4c4b400>;
					hactive = <0x238>;
					vactive = <0x4ba>;
					hback-porch = <0x104>;
					hfront-porch = <0xfa>;
					hsync-len = <0x04>;
					vback-porch = <0x0c>;
					vfront-porch = <0x0a>;
					vsync-len = <0x04>;
					hsync-active = <0x00>;
					vsync-active = <0x00>;
					de-active = <0x01>;
					pixelclk-active = <0x01>;
					phandle = <0xc4>;
				};
			};

			ports {
				#address-cells = <0x01>;
				#size-cells = <0x00>;

				port@0 {
					reg = <0x00>;

					endpoint {
						remote-endpoint = <0xc5>;
						phandle = <0xbf>;
					};
				};
			};
		};
	};

	phy@ffb20000 {
		compatible = "rockchip,rk3562-dsi-dphy", "rockchip,rk3562-video-phy", "rockchip,rk3568-dsi-dphy", "rockchip,rk3568-video-phy";
		reg = <0x00 0xffb20000 0x00 0x10000 0x00 0xffb10000 0x00 0x10000>;
		reg-names = "phy", "host";
		clocks = <0x02 0x13f 0x02 0x4d 0x02 0x4e>;
		clock-names = "ref", "pclk", "pclk_host";
		#clock-cells = <0x00>;
		resets = <0x02 0x198>;
		reset-names = "apb";
		#phy-cells = <0x00>;
		status = "okay";
		phandle = <0x44>;
	};

	pinctrl {
		compatible = "rockchip,rk3562-pinctrl";
		rockchip,grf = <0x76>;
		#address-cells = <0x02>;
		#size-cells = <0x02>;
		ranges;
		phandle = <0xc6>;

		gpio@ff260000 {
			compatible = "rockchip,gpio-bank";
			reg = <0x00 0xff260000 0x00 0x100>;
			interrupts = <0x00 0x00 0x04>;
			clocks = <0x02 0x11d 0x02 0x11e>;
			gpio-controller;
			#gpio-cells = <0x02>;
			gpio-ranges = <0xc6 0x00 0x00 0x20>;
			interrupt-controller;
			#interrupt-cells = <0x02>;
			phandle = <0x47>;
		};

		gpio@ff620000 {
			compatible = "rockchip,gpio-bank";
			reg = <0x00 0xff620000 0x00 0x100>;
			interrupts = <0x00 0x02 0x04>;
			clocks = <0x02 0x100 0x02 0x103>;
			gpio-controller;
			#gpio-cells = <0x02>;
			gpio-ranges = <0xc6 0x00 0x20 0x20>;
			interrupt-controller;
			#interrupt-cells = <0x02>;
			phandle = <0xd6>;
		};

		gpio@ff630000 {
			compatible = "rockchip,gpio-bank";
			reg = <0x00 0xff630000 0x00 0x100>;
			interrupts = <0x00 0x04 0x04>;
			clocks = <0x02 0x101 0x02 0x104>;
			gpio-controller;
			#gpio-cells = <0x02>;
			gpio-ranges = <0xc6 0x00 0x40 0x20>;
			interrupt-controller;
			#interrupt-cells = <0x02>;
			phandle = <0xe8>;
		};

		gpio@ffac0000 {
			compatible = "rockchip,gpio-bank";
			reg = <0x00 0xffac0000 0x00 0x100>;
			interrupts = <0x00 0x06 0x04>;
			clocks = <0x02 0x54 0x02 0x26>;
			gpio-controller;
			#gpio-cells = <0x02>;
			gpio-ranges = <0xc6 0x00 0x60 0x20>;
			interrupt-controller;
			#interrupt-cells = <0x02>;
			phandle = <0xb1>;
		};

		gpio@ffad0000 {
			compatible = "rockchip,gpio-bank";
			reg = <0x00 0xffad0000 0x00 0x100>;
			interrupts = <0x00 0x08 0x04>;
			clocks = <0x02 0x55 0x02 0x27>;
			gpio-controller;
			#gpio-cells = <0x02>;
			gpio-ranges = <0xc6 0x00 0x80 0x20>;
			interrupt-controller;
			#interrupt-cells = <0x02>;
			phandle = <0xb0>;
		};

		pcfg-pull-up {
			bias-pull-up;
			phandle = <0xcb>;
		};

		pcfg-pull-down {
			bias-pull-down;
			phandle = <0xd2>;
		};

		pcfg-pull-none {
			bias-disable;
			phandle = <0xc8>;
		};

		pcfg-pull-none-drv-level-1 {
			bias-disable;
			drive-strength = <0x01>;
			phandle = <0xcd>;
		};

		pcfg-pull-none-drv-level-2 {
			bias-disable;
			drive-strength = <0x02>;
			phandle = <0xd0>;
		};

		pcfg-pull-none-drv-level-3 {
			bias-disable;
			drive-strength = <0x03>;
			phandle = <0xce>;
		};

		pcfg-pull-none-drv-level-4 {
			bias-disable;
			drive-strength = <0x04>;
			phandle = <0xcf>;
		};

		pcfg-pull-up-drv-level-2 {
			bias-pull-up;
			drive-strength = <0x02>;
			phandle = <0xc9>;
		};

		pcfg-pull-down-drv-level-0 {
			bias-pull-down;
			drive-strength = <0x00>;
			phandle = <0xc7>;
		};

		pcfg-pull-none-smt {
			bias-disable;
			input-schmitt-enable;
			phandle = <0xca>;
		};

		pcfg-output-high {
			output-high;
			phandle = <0xd1>;
		};

		pcfg-output-low {
			output-low;
			phandle = <0xcc>;
		};

		cam {

			camm0-clk0-out {
				rockchip,pins = <0x03 0x0a 0x02 0xc7>;
				phandle = <0xb4>;
			};

			camm0-clk1-out {
				rockchip,pins = <0x03 0x0b 0x02 0xc8>;
				phandle = <0xbb>;
			};
		};

		dsm {

			dsm-pins {
				rockchip,pins = <0x01 0x0c 0x05 0xc8 0x01 0x0b 0x05 0xc8 0x01 0x0e 0x06 0xc8 0x01 0x0d 0x06 0xc8>;
				phandle = <0xa5>;
			};
		};

		emmc {
		};

		i2c0 {

			i2c0-xfer {
				rockchip,pins = <0x00 0x09 0x01 0xca 0x00 0x0a 0x01 0xca>;
				phandle = <0x46>;
			};
		};

		i2c1 {

			i2c1m0-xfer {
				rockchip,pins = <0x00 0x0b 0x01 0xca 0x00 0x0c 0x01 0xca>;
				phandle = <0xa9>;
			};
		};

		i2c2 {

			i2c2m0-xfer {
				rockchip,pins = <0x00 0x0d 0x01 0xca 0x00 0x0e 0x01 0xca>;
				phandle = <0xab>;
			};
		};

		i2c3 {

			i2c3m0-xfer {
				rockchip,pins = <0x03 0x00 0x01 0xca 0x03 0x01 0x01 0xca>;
				phandle = <0xaf>;
			};
		};

		i2c4 {

			i2c4m0-xfer {
				rockchip,pins = <0x03 0x0e 0x05 0xca 0x03 0x0f 0x05 0xca>;
				phandle = <0xb3>;
			};
		};

		i2c5 {

			i2c5m0-xfer {
				rockchip,pins = <0x03 0x12 0x01 0xca 0x03 0x13 0x01 0xca>;
				phandle = <0xb9>;
			};
		};

		i2s0 {

			i2s0m0-lrck {
				rockchip,pins = <0x03 0x04 0x01 0xc8>;
				phandle = <0x90>;
			};

			i2s0m0-sclk {
				rockchip,pins = <0x03 0x03 0x01 0xc8>;
				phandle = <0x91>;
			};

			i2s0m0-sdi0 {
				rockchip,pins = <0x03 0x09 0x01 0xc8>;
				phandle = <0x92>;
			};

			i2s0m0-sdo0 {
				rockchip,pins = <0x03 0x05 0x01 0xc8>;
				phandle = <0x93>;
			};
		};

		i2s1 {

			i2s1m0-lrck {
				rockchip,pins = <0x03 0x16 0x02 0xc8>;
				phandle = <0x94>;
			};

			i2s1m0-sclk {
				rockchip,pins = <0x03 0x15 0x02 0xc8>;
				phandle = <0x95>;
			};

			i2s1m0-sdi0 {
				rockchip,pins = <0x03 0x18 0x02 0xc8>;
				phandle = <0x96>;
			};

			i2s1m0-sdi1 {
				rockchip,pins = <0x03 0x19 0x02 0xc8>;
				phandle = <0x97>;
			};

			i2s1m0-sdi2 {
				rockchip,pins = <0x03 0x1a 0x02 0xc8>;
				phandle = <0x98>;
			};

			i2s1m0-sdi3 {
				rockchip,pins = <0x03 0x1b 0x02 0xc8>;
				phandle = <0x99>;
			};

			i2s1m0-sdo0 {
				rockchip,pins = <0x03 0x17 0x02 0xc8>;
				phandle = <0x9a>;
			};

			i2s1m0-sdo1 {
				rockchip,pins = <0x04 0x0c 0x02 0xc8>;
				phandle = <0x9b>;
			};

			i2s1m0-sdo2 {
				rockchip,pins = <0x04 0x0d 0x02 0xc8>;
				phandle = <0x9c>;
			};

			i2s1m0-sdo3 {
				rockchip,pins = <0x04 0x0e 0x02 0xc8>;
				phandle = <0x9d>;
			};
		};

		i2s2 {

			i2s2m0-lrck {
				rockchip,pins = <0x01 0x1e 0x01 0xc8>;
				phandle = <0x9e>;
			};

			i2s2m0-sclk {
				rockchip,pins = <0x01 0x1d 0x01 0xc8>;
				phandle = <0x9f>;
			};

			i2s2m0-sdi {
				rockchip,pins = <0x02 0x00 0x01 0xc8>;
				phandle = <0xa0>;
			};

			i2s2m0-sdo {
				rockchip,pins = <0x01 0x1f 0x01 0xc8>;
				phandle = <0xa1>;
			};
		};

		pdm {

			pdmm0-clk0 {
				rockchip,pins = <0x03 0x06 0x03 0xc8>;
				phandle = <0xa2>;
			};

			pdmm0-clk1 {
				rockchip,pins = <0x03 0x02 0x03 0xc8>;
				phandle = <0x52>;
			};

			pdmm0-sdi1 {
				rockchip,pins = <0x03 0x08 0x03 0xc8>;
				phandle = <0xa3>;
			};
		};

		pmic {

			pmic-int {
				rockchip,pins = <0x00 0x03 0x00 0xcb>;
				phandle = <0x48>;
			};

			soc-slppin-gpio {
				rockchip,pins = <0x00 0x02 0x00 0xcc>;
				phandle = <0x4b>;
			};

			soc-slppin-slp {
				rockchip,pins = <0x00 0x02 0x01 0xc8>;
				phandle = <0x49>;
			};
		};

		pwm0 {

			pwm0m0-pins {
				rockchip,pins = <0x00 0x13 0x02 0xcd>;
				phandle = <0x58>;
			};
		};

		pwm1 {

			pwm1m0-pins {
				rockchip,pins = <0x00 0x14 0x02 0xcd>;
				phandle = <0x59>;
			};
		};

		pwm2 {

			pwm2m0-pins {
				rockchip,pins = <0x00 0x15 0x02 0xcd>;
				phandle = <0x5a>;
			};
		};

		pwm3 {

			pwm3m0-pins {
				rockchip,pins = <0x00 0x07 0x01 0xcd>;
				phandle = <0x5b>;
			};
		};

		pwm4 {

			pwm4m0-pins {
				rockchip,pins = <0x00 0x0f 0x02 0xcd>;
				phandle = <0x7f>;
			};
		};

		pwm5 {

			pwm5m0-pins {
				rockchip,pins = <0x00 0x12 0x02 0xcd>;
				phandle = <0x80>;
			};
		};

		pwm6 {

			pwm6m0-pins {
				rockchip,pins = <0x00 0x11 0x02 0xcd>;
				phandle = <0x81>;
			};
		};

		pwm7 {

			pwm7m0-pins {
				rockchip,pins = <0x00 0x10 0x02 0xcd>;
				phandle = <0x82>;
			};
		};

		pwm8 {

			pwm8m0-pins {
				rockchip,pins = <0x03 0x04 0x02 0xcd>;
				phandle = <0x83>;
			};
		};

		pwm9 {

			pwm9m0-pins {
				rockchip,pins = <0x03 0x05 0x02 0xcd>;
				phandle = <0x84>;
			};
		};

		pwm10 {

			pwm10m0-pins {
				rockchip,pins = <0x01 0x0d 0x05 0xcd>;
				phandle = <0x85>;
			};
		};

		pwm11 {

			pwm11m0-pins {
				rockchip,pins = <0x01 0x0e 0x05 0xcd>;
				phandle = <0x86>;
			};
		};

		pwm12 {

			pwm12m0-pins {
				rockchip,pins = <0x04 0x01 0x04 0xcd>;
				phandle = <0x87>;
			};
		};

		pwm13 {

			pwm13m0-pins {
				rockchip,pins = <0x04 0x04 0x03 0xcd>;
				phandle = <0x88>;
			};
		};

		pwm14 {

			pwm14m0-pins {
				rockchip,pins = <0x03 0x15 0x04 0xcd>;
				phandle = <0x89>;
			};
		};

		pwm15 {

			pwm15m0-pins {
				rockchip,pins = <0x03 0x16 0x04 0xcd>;
				phandle = <0x8a>;
			};
		};

		sdmmc1 {

			sdmmc1-bus4 {
				rockchip,pins = <0x01 0x11 0x01 0xc9 0x01 0x12 0x01 0xc9 0x01 0x13 0x01 0xc9 0x01 0x14 0x01 0xc9>;
				phandle = <0xa6>;
			};

			sdmmc1-clk {
				rockchip,pins = <0x01 0x16 0x01 0xc9>;
				phandle = <0xa8>;
			};

			sdmmc1-cmd {
				rockchip,pins = <0x01 0x15 0x01 0xc9>;
				phandle = <0xa7>;
			};
		};

		spdif {

			spdifm0-pins {
				rockchip,pins = <0x03 0x01 0x03 0xc8>;
				phandle = <0xa4>;
			};
		};

		spi0 {

			spi0m0-pins {
				rockchip,pins = <0x00 0x13 0x03 0xce 0x00 0x15 0x03 0xce 0x00 0x14 0x03 0xce>;
				phandle = <0x57>;
			};

			spi0m0-csn0 {
				rockchip,pins = <0x00 0x12 0x03 0xce>;
				phandle = <0x56>;
			};
		};

		uart0 {

			uart0m0-xfer {
				rockchip,pins = <0x00 0x18 0x01 0xcb 0x00 0x19 0x01 0xcb>;
				phandle = <0xd3>;
			};
		};

		uart1 {

			uart1m0-xfer {
				rockchip,pins = <0x01 0x19 0x01 0xcb 0x01 0x1a 0x01 0xcb>;
				phandle = <0x7d>;
			};

			uart1m0-ctsn {
				rockchip,pins = <0x01 0x1c 0x01 0xc8>;
				phandle = <0x7e>;
			};

			uart1m0-rtsn {
				rockchip,pins = <0x01 0x1b 0x01 0xc8>;
				phandle = <0xe9>;
			};
		};

		uart4 {

			uart4m0-xfer {
				rockchip,pins = <0x03 0x19 0x03 0xcb 0x03 0x18 0x03 0xcb>;
				phandle = <0xed>;
			};
		};

		uart8 {

			uart8m1-xfer {
				rockchip,pins = <0x03 0x1d 0x03 0xcb 0x03 0x1c 0x03 0xcb>;
				phandle = <0xef>;
			};
		};

		vo {

			vo-pins {
				rockchip,pins = <0x04 0x0f 0x01 0xc8 0x04 0x04 0x01 0xc8 0x04 0x05 0x01 0xc8 0x04 0x0a 0x01 0xc8 0x03 0x14 0x01 0xc8 0x03 0x15 0x01 0xc8 0x03 0x16 0x01 0xc8 0x03 0x17 0x01 0xc8 0x03 0x18 0x01 0xc8 0x04 0x06 0x01 0xc8 0x04 0x07 0x01 0xc8 0x03 0x19 0x01 0xc8 0x03 0x1a 0x01 0xc8 0x03 0x1b 0x01 0xc8 0x03 0x1c 0x01 0xc8 0x03 0x1d 0x01 0xc8 0x03 0x1e 0x01 0xc8 0x04 0x08 0x01 0xc8 0x04 0x09 0x01 0xc8 0x04 0x0b 0x01 0xc8 0x03 0x1f 0x01 0xc8 0x04 0x00 0x01 0xc8 0x04 0x01 0x01 0xc8 0x04 0x02 0x01 0xc8 0x04 0x03 0x01 0xc8 0x04 0x0e 0x01 0xc8 0x04 0x0c 0x01 0xc8 0x04 0x0d 0x01 0xc8>;
				phandle = <0x45>;
			};
		};

		flash_led {

			flash-led-white-gpio {
				rockchip,pins = <0x01 0x0b 0x00 0xcc>;
				phandle = <0xd4>;
			};

			flash-led-ir-gpio {
				rockchip,pins = <0x01 0x0c 0x00 0xcc>;
				phandle = <0xd5>;
			};
		};

		camera_keys {

			camera-left-gpio {
				rockchip,pins = <0x00 0x06 0x00 0xcb>;
				phandle = <0xd7>;
			};
		};

		led_control {

			led-left-gpio {
				rockchip,pins = <0x00 0x06 0x00 0xcb>;
				phandle = <0xd8>;
			};

			led-white-gpio {
				rockchip,pins = <0x01 0x0b 0x00 0xc8>;
				phandle = <0xd9>;
			};

			led-ir-gpio {
				rockchip,pins = <0x01 0x0c 0x00 0xc8>;
				phandle = <0xda>;
			};
		};

		af_gpio {

			af_gpio_pwr {
				rockchip,pins = <0x03 0x0d 0x00 0xd1>;
				phandle = <0xe2>;
			};
		};

		gpio_keys {

			home-key {
				rockchip,pins = <0x00 0x04 0x00 0xcb>;
				phandle = <0xdb>;
			};

			hall-up {
				rockchip,pins = <0x00 0x12 0x00 0xcb>;
				phandle = <0xdd>;
			};

			hall-down {
				rockchip,pins = <0x00 0x07 0x00 0xcb>;
				phandle = <0xdc>;
			};
		};

		lcd {

			lcd-rst-gpio {
				rockchip,pins = <0x04 0x0e 0x00 0xc8>;
				phandle = <0xc1>;
			};

			lcd-power-en {
				rockchip,pins = <0x04 0x0f 0x00 0xc8>;
				phandle = <0xc2>;
			};

			lcd-gpio {
				rockchip,pins = <0x03 0x16 0x00 0xc8>;
				phandle = <0xc3>;
			};
		};

		tp {

			tp-rst-gpio {
				rockchip,pins = <0x00 0x0e 0x00 0xc8>;
			};

			tp-irq-gpio {
				rockchip,pins = <0x00 0x0d 0x00 0xcb>;
			};
		};

		usb {

			usbc0-int {
				rockchip,pins = <0x00 0x15 0x00 0xcb>;
				phandle = <0x53>;
			};
		};

		sdio-pwrseq {

			wifi-enable-h {
				rockchip,pins = <0x03 0x14 0x00 0xc8>;
				phandle = <0xe4>;
			};
		};

		wireless-wlan {

			wifi-host-wake-irq {
				rockchip,pins = <0x02 0x01 0x00 0xd2>;
				phandle = <0xe5>;
			};

			wifi-poweren-gpio {
				rockchip,pins = <0x03 0x14 0x00 0xd2>;
				phandle = <0xe6>;
			};

			wifi-host-wakeup {
				rockchip,pins = <0x01 0x17 0x00 0xd2>;
				phandle = <0xe7>;
			};
		};

		wireless-bluetooth {

			uart1-gpios {
				rockchip,pins = <0x01 0x1b 0x00 0xc8>;
				phandle = <0xeb>;
			};

			bt-reset-gpio {
				rockchip,pins = <0x01 0x1e 0x00 0xd2>;
				phandle = <0xea>;
			};
		};

		rk817_codec {

			fs-en-gpio {
				rockchip,pins = <0x03 0x1d 0x00 0xd2>;
			};
		};

		aw883xx {

			aw-rst-gpio {
				rockchip,pins = <0x04 0x0b 0x00 0xd2>;
				phandle = <0xb2>;
			};
		};

		mir3_int {

			mir3-gpio {
				rockchip,pins = <0x00 0x05 0x00 0xcb>;
				phandle = <0xac>;
			};
		};

		aw8680x {

			reset-gpio {
				rockchip,pins = <0x00 0x14 0x00 0xd2>;
				phandle = <0xad>;
			};

			wake-gpio {
				rockchip,pins = <0x00 0x13 0x00 0xd2>;
				phandle = <0xae>;
			};
		};

		lte_pwr_en {

			pwr-en-gpio {
				rockchip,pins = <0x00 0x08 0x00 0xd1>;
				phandle = <0xee>;
			};
		};
	};

	rockchip-suspend {
		compatible = "rockchip,pm-rk3562";
		status = "okay";
		rockchip,sleep-debug-en = <0x01>;
		rockchip,sleep-mode-config = <0x5e2>;
		rockchip,wakeup-config = <0x10>;
	};

	chosen {
		bootargs = "earlycon=uart8250,mmio32,0xff210000 console=ttyFIQ0";
	};

	fiq-debugger {
		compatible = "rockchip,fiq-debugger";
		rockchip,serial-id = <0x00>;
		rockchip,wake-irq = <0x00>;
		rockchip,irq-mode-enable = <0x01>;
		rockchip,baudrate = <0x16e360>;
		interrupts = <0x00 0xf2 0x04>;
		pinctrl-names = "default";
		pinctrl-0 = <0xd3>;
		status = "okay";
	};

	led_control {
		status = "okay";
		compatible = "led_control";
		debounce-interval = <0x01>;
		wakeup-source;
		pinctrl-names = "default";
		pinctrl-0 = <0xd8 0xd9 0xda>;
		left_gpio = <0x47 0x06 0x01>;
		white-gpio = <0xd6 0x0b 0x00>;
		ir-gpio = <0xd6 0x0c 0x00>;
		hall-down = <0x47 0x12 0x01>;
	};

	gpio-keys {
		compatible = "gpio-keys";
		pinctrl-names = "default";
		pinctrl-0 = <0xdb 0xdc 0xdd>;

		home-key {
			gpios = <0x47 0x04 0x01>;
			linux,code = <0x66>;
			label = "Home Key";
			debounce-interval = <0x19>;
			wakeup-source;
		};

		hall@1 {
			label = "hall-down";
			linux,code = <0x05>;
			linux,input-type = <0x05>;
			gpio = <0x47 0x12 0x01>;
			debounce-interval = <0x32>;
			wakeup-source;
		};

		hall@2 {
			label = "hall-up";
			linux,code = <0x0a>;
			linux,input-type = <0x05>;
			gpio = <0x47 0x07 0x01>;
			debounce-interval = <0x32>;
			wakeup-source;
		};
	};

	charge-animation {
		compatible = "rockchip,uboot-charge";
		rockchip,uboot-charge-on = <0x00>;
		rockchip,android-charge-on = <0x00>;
		rockchip,uboot-low-power-voltage = <0xce4>;
		rockchip,screen-on-voltage = <0xd48>;
		rockchip,auto-wakeup-interval = <0x0a>;
		status = "okay";
	};

	dummy-codec {
		status = "okay";
		compatible = "rockchip,dummy-codec";
		#sound-dai-cells = <0x00>;
	};

	pdm-rk817codec-adc {
		status = "okay";
		compatible = "simple-audio-card";
		simple-audio-card,name = "rockchip,pdm-rk817codec-adc";

		simple-audio-card,cpu {
			sound-dai = <0xde>;
		};

		simple-audio-card,codec {
			sound-dai = <0xdf>;
		};
	};

	aw883x-sound {
		status = "okay";
		compatible = "rockchip,multicodecs-card";
		rockchip,card-name = "rockchip-aw883xx";
		rockchip,format = "i2s";
		rockchip,mclk-fs = <0x100>;
		rockchip,cpu = <0xe0>;
		rockchip,codec = <0xe1>;
	};

	vcc_af_2v8 {
		compatible = "regulator-fixed";
		pinctrl-names = "default";
		pinctrl-0 = <0xe2>;
		regulator-name = "vcc_af_2v8";
		gpio = <0xb1 0x0d 0x00>;
		enable-active-high;
		phandle = <0xba>;

		regulator-state-mem {
			regulator-off-in-suspend;
		};
	};

	vcc-sys {
		compatible = "regulator-fixed";
		regulator-name = "vcc_sys";
		regulator-always-on;
		regulator-boot-on;
		regulator-min-microvolt = <0x39fbc0>;
		regulator-max-microvolt = <0x39fbc0>;
		phandle = <0x4e>;
	};

	wireless-wlan {
		compatible = "wlan-platdata";
		rockchip,grf = <0x0d>;
		wifi_chip_type = "bes2600";
		pinctrl-names = "default";
		pinctrl-0 = <0xe5 0xe6 0xe7>;
		WIFI,host_wake_irq = <0xe8 0x01 0x00>;
		WIFI,poweren_gpio = <0xb0 0x05 0x00>;
		WIFI,host_wakeup_wifi = <0xd6 0x17 0x01>;
		status = "okay";
	};

	wireless-bluetooth {
		compatible = "bluetooth-platdata";
		clocks = <0xe3 0x01>;
		clock-names = "ext_clock";
		uart_rts_gpios = <0xd6 0x1b 0x01>;
		pinctrl-names = "default", "rts_gpio";
		pinctrl-0 = <0xe9 0xea>;
		pinctrl-1 = <0xeb>;
		BT,reset_gpio = <0xd6 0x1e 0x00>;
		status = "okay";
	};

	adb_mtp_notify {
		status = "okay";
		compatible = "youdao,usb_device_notify";
		usb-device-name = "adb_mtp";
		extcon = <0xec>;
	};

	serial@ff6a0000 {
		compatible = "rockchip,rk3562-uart", "snps,dw-apb-uart";
		reg = <0x00 0xff6a0000 0x00 0x100>;
		interrupts = <0x00 0x22 0x04>;
		clocks = <0x02 0xbe 0x02 0xa9>;
		clock-names = "baudclk", "apb_pclk";
		reg-shift = <0x02>;
		reg-io-width = <0x04>;
		dmas = <0x55 0x04>;
		status = "okay";
		pinctrl-names = "default";
		pinctrl-0 = <0xed 0xee>;
	};

	serial@ff6e0000 {
		compatible = "rockchip,rk3562-uart", "snps,dw-apb-uart";
		reg = <0x00 0xff6e0000 0x00 0x100>;
		interrupts = <0x00 0x26 0x04>;
		clocks = <0x02 0xce 0x02 0xad>;
		clock-names = "baudclk", "apb_pclk";
		reg-shift = <0x02>;
		reg-io-width = <0x04>;
		dmas = <0x55 0x08>;
		status = "okay";
		pinctrl-names = "default";
		pinctrl-0 = <0xef>;
	};
};
